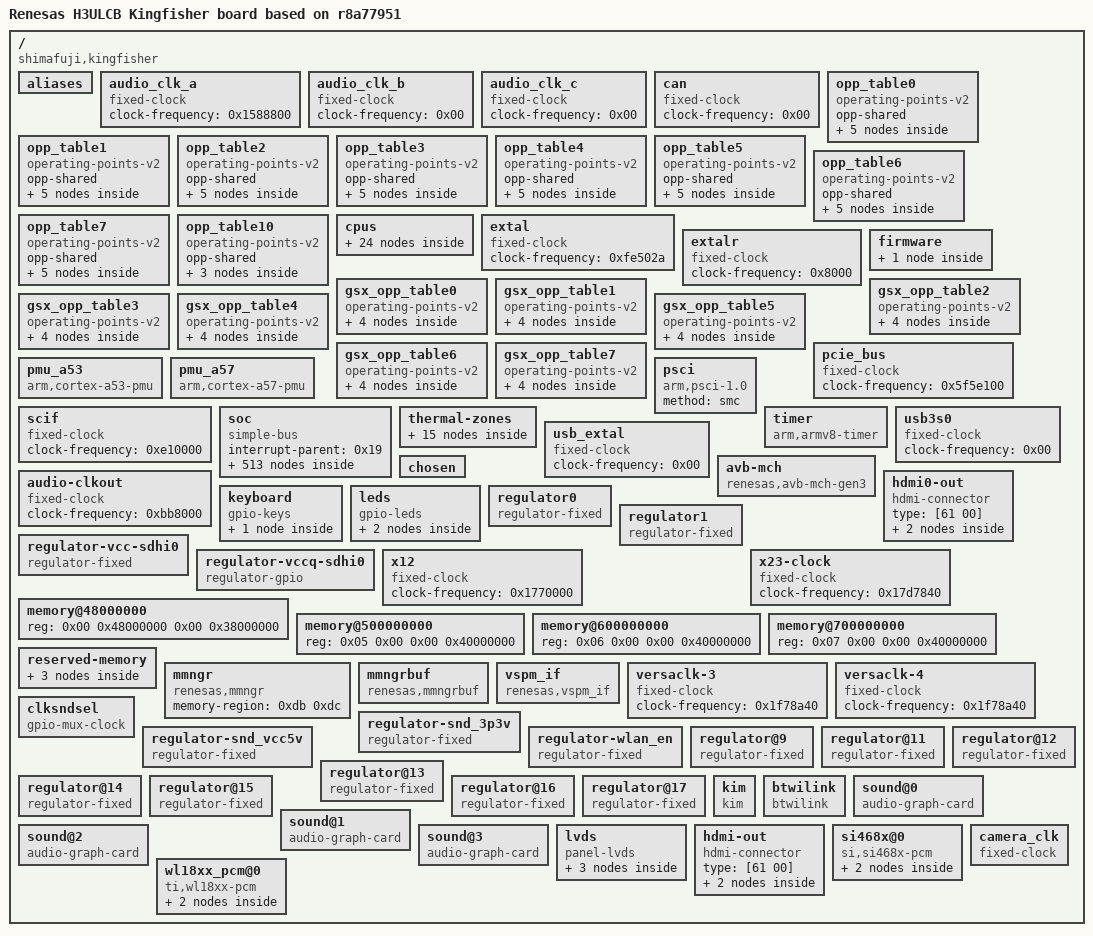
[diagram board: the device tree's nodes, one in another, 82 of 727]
/dts-v1/;

/ {
	compatible = "shimafuji,kingfisher\0renesas,h3ulcb\0renesas,r8a7795";
	#address-cells = <0x02>;
	#size-cells = <0x02>;
	model = "Renesas H3ULCB Kingfisher board based on r8a77951";

	aliases {
		i2c0 = "/soc/i2c@e6500000";
		i2c1 = "/soc/i2c@e6508000";
		i2c2 = "/soc/i2c@e6510000";
		i2c3 = "/soc/i2c@e66d0000";
		i2c4 = "/soc/i2c@e66d8000";
		i2c5 = "/soc/i2c@e66e0000";
		i2c6 = "/soc/i2c@e66e8000";
		i2c7 = "/soc/i2c@e60b0000";
		spi0 = "/soc/spi@e6e90000";
		spi1 = "/soc/spi@e6ea0000";
		spi2 = "/soc/spi@e6c00000";
		spi3 = "/soc/spi@e6c10000";
		serial0 = "/soc/serial@e6e88000";
		ethernet0 = "/soc/ethernet@e6800000";
		mmc0 = "/soc/mmc@ee140000";
		mmc1 = "/soc/mmc@ee100000";
		serial1 = "/soc/serial@e6540000";
		serial2 = "/soc/serial@e6e68000";
		serial3 = "/soc/serial@e6550000";
		mmc2 = "/soc/mmc@ee160000";
	};

	audio_clk_a {
		compatible = "fixed-clock";
		#clock-cells = <0x00>;
		clock-frequency = <0x1588800>;
		phandle = <0x77>;
	};

	audio_clk_b {
		compatible = "fixed-clock";
		#clock-cells = <0x00>;
		clock-frequency = <0x00>;
	};

	audio_clk_c {
		compatible = "fixed-clock";
		#clock-cells = <0x00>;
		clock-frequency = <0x00>;
		phandle = <0x78>;
	};

	can {
		compatible = "fixed-clock";
		#clock-cells = <0x00>;
		clock-frequency = <0x00>;
		phandle = <0x56>;
	};

	opp_table0 {
		compatible = "operating-points-v2";
		opp-shared;
		phandle = <0x0d>;

		opp-500000000 {
			opp-hz = <0x00 0x1dcd6500>;
			opp-microvolt = <0xcaa30>;
			clock-latency-ns = <0x493e0>;
		};

		opp-1000000000 {
			opp-hz = <0x00 0x3b9aca00>;
			opp-microvolt = <0xcaa30>;
			clock-latency-ns = <0x493e0>;
		};

		opp-1500000000 {
			opp-hz = <0x00 0x59682f00>;
			opp-microvolt = <0xcaa30>;
			clock-latency-ns = <0x493e0>;
			opp-suspend;
		};

		opp-1600000000 {
			opp-hz = <0x00 0x5f5e1000>;
			opp-microvolt = <0xdbba0>;
			clock-latency-ns = <0x493e0>;
			turbo-mode;
		};

		opp-1700000000 {
			opp-hz = <0x00 0x6553f100>;
			opp-microvolt = <0xea600>;
			clock-latency-ns = <0x493e0>;
			turbo-mode;
		};
	};

	opp_table1 {
		compatible = "operating-points-v2";
		opp-shared;
		phandle = <0x0e>;

		opp-500000000 {
			opp-hz = <0x00 0x1dcd6500>;
			opp-microvolt = <0xc8320>;
			clock-latency-ns = <0x493e0>;
		};

		opp-1000000000 {
			opp-hz = <0x00 0x3b9aca00>;
			opp-microvolt = <0xc8320>;
			clock-latency-ns = <0x493e0>;
		};

		opp-1500000000 {
			opp-hz = <0x00 0x59682f00>;
			opp-microvolt = <0xc8320>;
			clock-latency-ns = <0x493e0>;
			opp-suspend;
		};

		opp-1600000000 {
			opp-hz = <0x00 0x5f5e1000>;
			opp-microvolt = <0xd9490>;
			clock-latency-ns = <0x493e0>;
			turbo-mode;
		};

		opp-1700000000 {
			opp-hz = <0x00 0x6553f100>;
			opp-microvolt = <0xe7ef0>;
			clock-latency-ns = <0x493e0>;
			turbo-mode;
		};
	};

	opp_table2 {
		compatible = "operating-points-v2";
		opp-shared;
		phandle = <0x0f>;

		opp-500000000 {
			opp-hz = <0x00 0x1dcd6500>;
			opp-microvolt = <0xc5c10>;
			clock-latency-ns = <0x493e0>;
		};

		opp-1000000000 {
			opp-hz = <0x00 0x3b9aca00>;
			opp-microvolt = <0xc5c10>;
			clock-latency-ns = <0x493e0>;
		};

		opp-1500000000 {
			opp-hz = <0x00 0x59682f00>;
			opp-microvolt = <0xc5c10>;
			clock-latency-ns = <0x493e0>;
			opp-suspend;
		};

		opp-1600000000 {
			opp-hz = <0x00 0x5f5e1000>;
			opp-microvolt = <0xd6d80>;
			clock-latency-ns = <0x493e0>;
			turbo-mode;
		};

		opp-1700000000 {
			opp-hz = <0x00 0x6553f100>;
			opp-microvolt = <0xe30d0>;
			clock-latency-ns = <0x493e0>;
			turbo-mode;
		};
	};

	opp_table3 {
		compatible = "operating-points-v2";
		opp-shared;
		phandle = <0x10>;

		opp-500000000 {
			opp-hz = <0x00 0x1dcd6500>;
			opp-microvolt = <0xc3500>;
			clock-latency-ns = <0x493e0>;
		};

		opp-1000000000 {
			opp-hz = <0x00 0x3b9aca00>;
			opp-microvolt = <0xc3500>;
			clock-latency-ns = <0x493e0>;
		};

		opp-1500000000 {
			opp-hz = <0x00 0x59682f00>;
			opp-microvolt = <0xc3500>;
			clock-latency-ns = <0x493e0>;
			opp-suspend;
		};

		opp-1600000000 {
			opp-hz = <0x00 0x5f5e1000>;
			opp-microvolt = <0xd4670>;
			clock-latency-ns = <0x493e0>;
			turbo-mode;
		};

		opp-1700000000 {
			opp-hz = <0x00 0x6553f100>;
			opp-microvolt = <0xde2b0>;
			clock-latency-ns = <0x493e0>;
			turbo-mode;
		};
	};

	opp_table4 {
		compatible = "operating-points-v2";
		opp-shared;
		phandle = <0x11>;

		opp-500000000 {
			opp-hz = <0x00 0x1dcd6500>;
			opp-microvolt = <0xc0df0>;
			clock-latency-ns = <0x493e0>;
		};

		opp-1000000000 {
			opp-hz = <0x00 0x3b9aca00>;
			opp-microvolt = <0xc0df0>;
			clock-latency-ns = <0x493e0>;
		};

		opp-1500000000 {
			opp-hz = <0x00 0x59682f00>;
			opp-microvolt = <0xc0df0>;
			clock-latency-ns = <0x493e0>;
			opp-suspend;
		};

		opp-1600000000 {
			opp-hz = <0x00 0x5f5e1000>;
			opp-microvolt = <0xd1f60>;
			clock-latency-ns = <0x493e0>;
			turbo-mode;
		};

		opp-1700000000 {
			opp-hz = <0x00 0x6553f100>;
			opp-microvolt = <0xd9490>;
			clock-latency-ns = <0x493e0>;
			turbo-mode;
		};
	};

	opp_table5 {
		compatible = "operating-points-v2";
		opp-shared;
		phandle = <0x12>;

		opp-500000000 {
			opp-hz = <0x00 0x1dcd6500>;
			opp-microvolt = <0xbe6e0>;
			clock-latency-ns = <0x493e0>;
		};

		opp-1000000000 {
			opp-hz = <0x00 0x3b9aca00>;
			opp-microvolt = <0xbe6e0>;
			clock-latency-ns = <0x493e0>;
		};

		opp-1500000000 {
			opp-hz = <0x00 0x59682f00>;
			opp-microvolt = <0xbe6e0>;
			clock-latency-ns = <0x493e0>;
			opp-suspend;
		};

		opp-1600000000 {
			opp-hz = <0x00 0x5f5e1000>;
			opp-microvolt = <0xcf850>;
			clock-latency-ns = <0x493e0>;
			turbo-mode;
		};

		opp-1700000000 {
			opp-hz = <0x00 0x6553f100>;
			opp-microvolt = <0xd6d80>;
			clock-latency-ns = <0x493e0>;
			turbo-mode;
		};
	};

	opp_table6 {
		compatible = "operating-points-v2";
		opp-shared;
		phandle = <0x13>;

		opp-500000000 {
			opp-hz = <0x00 0x1dcd6500>;
			opp-microvolt = <0xbbfd0>;
			clock-latency-ns = <0x493e0>;
		};

		opp-1000000000 {
			opp-hz = <0x00 0x3b9aca00>;
			opp-microvolt = <0xbbfd0>;
			clock-latency-ns = <0x493e0>;
		};

		opp-1500000000 {
			opp-hz = <0x00 0x59682f00>;
			opp-microvolt = <0xbbfd0>;
			clock-latency-ns = <0x493e0>;
			opp-suspend;
		};

		opp-1600000000 {
			opp-hz = <0x00 0x5f5e1000>;
			opp-microvolt = <0xcd140>;
			clock-latency-ns = <0x493e0>;
			turbo-mode;
		};

		opp-1700000000 {
			opp-hz = <0x00 0x6553f100>;
			opp-microvolt = <0xd4670>;
			clock-latency-ns = <0x493e0>;
			turbo-mode;
		};
	};

	opp_table7 {
		compatible = "operating-points-v2";
		opp-shared;
		phandle = <0x14>;

		opp-500000000 {
			opp-hz = <0x00 0x1dcd6500>;
			opp-microvolt = <0xb98c0>;
			clock-latency-ns = <0x493e0>;
		};

		opp-1000000000 {
			opp-hz = <0x00 0x3b9aca00>;
			opp-microvolt = <0xb98c0>;
			clock-latency-ns = <0x493e0>;
		};

		opp-1500000000 {
			opp-hz = <0x00 0x59682f00>;
			opp-microvolt = <0xb98c0>;
			clock-latency-ns = <0x493e0>;
			opp-suspend;
		};

		opp-1600000000 {
			opp-hz = <0x00 0x5f5e1000>;
			opp-microvolt = <0xcaa30>;
			clock-latency-ns = <0x493e0>;
			turbo-mode;
		};

		opp-1700000000 {
			opp-hz = <0x00 0x6553f100>;
			opp-microvolt = <0xd1f60>;
			clock-latency-ns = <0x493e0>;
			turbo-mode;
		};
	};

	opp_table10 {
		compatible = "operating-points-v2";
		opp-shared;
		phandle = <0x18>;

		opp-800000000 {
			opp-hz = <0x00 0x2faf0800>;
			opp-microvolt = <0xc8320>;
			clock-latency-ns = <0x493e0>;
		};

		opp-1000000000 {
			opp-hz = <0x00 0x3b9aca00>;
			opp-microvolt = <0xc8320>;
			clock-latency-ns = <0x493e0>;
		};

		opp-1200000000 {
			opp-hz = <0x00 0x47868c00>;
			opp-microvolt = <0xc8320>;
			clock-latency-ns = <0x493e0>;
			opp-suspend;
		};
	};

	cpus {
		#address-cells = <0x01>;
		#size-cells = <0x00>;

		cpu-map {

			cluster0 {

				core0 {
					cpu = <0x01>;
				};

				core1 {
					cpu = <0x02>;
				};

				core2 {
					cpu = <0x03>;
				};

				core3 {
					cpu = <0x04>;
				};
			};

			cluster1 {

				core0 {
					cpu = <0x05>;
				};

				core1 {
					cpu = <0x06>;
				};

				core2 {
					cpu = <0x07>;
				};

				core3 {
					cpu = <0x08>;
				};
			};
		};

		cpu@0 {
			compatible = "arm,cortex-a57";
			reg = <0x00>;
			device_type = "cpu";
			power-domains = <0x09 0x00>;
			next-level-cache = <0x0a>;
			enable-method = "psci";
			cpu-idle-states = <0x0b>;
			dynamic-power-coefficient = <0x356>;
			cooling-min-level = <0x00>;
			cooling-max-level = <0x02>;
			clocks = <0x0c 0x00 0x00>;
			operating-points-v2 = <0x0d 0x0e 0x0f 0x10 0x11 0x12 0x13 0x14>;
			capacity-dmips-mhz = <0x400>;
			#cooling-cells = <0x02>;
			cpu-supply = <0x15>;
			phandle = <0x01>;
		};

		cpu@1 {
			compatible = "arm,cortex-a57";
			reg = <0x01>;
			device_type = "cpu";
			power-domains = <0x09 0x01>;
			next-level-cache = <0x0a>;
			enable-method = "psci";
			cpu-idle-states = <0x0b>;
			clocks = <0x0c 0x00 0x00>;
			operating-points-v2 = <0x0d 0x0e 0x0f 0x10 0x11 0x12 0x13 0x14>;
			capacity-dmips-mhz = <0x400>;
			#cooling-cells = <0x02>;
			phandle = <0x02>;
		};

		cpu@2 {
			compatible = "arm,cortex-a57";
			reg = <0x02>;
			device_type = "cpu";
			power-domains = <0x09 0x02>;
			next-level-cache = <0x0a>;
			enable-method = "psci";
			cpu-idle-states = <0x0b>;
			clocks = <0x0c 0x00 0x00>;
			operating-points-v2 = <0x0d 0x0e 0x0f 0x10 0x11 0x12 0x13 0x14>;
			capacity-dmips-mhz = <0x400>;
			#cooling-cells = <0x02>;
			phandle = <0x03>;
		};

		cpu@3 {
			compatible = "arm,cortex-a57";
			reg = <0x03>;
			device_type = "cpu";
			power-domains = <0x09 0x03>;
			next-level-cache = <0x0a>;
			enable-method = "psci";
			cpu-idle-states = <0x0b>;
			clocks = <0x0c 0x00 0x00>;
			operating-points-v2 = <0x0d 0x0e 0x0f 0x10 0x11 0x12 0x13 0x14>;
			capacity-dmips-mhz = <0x400>;
			#cooling-cells = <0x02>;
			phandle = <0x04>;
		};

		cpu@100 {
			compatible = "arm,cortex-a53";
			reg = <0x100>;
			device_type = "cpu";
			power-domains = <0x09 0x05>;
			next-level-cache = <0x16>;
			enable-method = "psci";
			cpu-idle-states = <0x17>;
			#cooling-cells = <0x02>;
			dynamic-power-coefficient = <0x115>;
			cooling-min-level = <0x00>;
			cooling-max-level = <0x02>;
			clocks = <0x0c 0x00 0x01>;
			operating-points-v2 = <0x18>;
			capacity-dmips-mhz = <0x21c>;
			phandle = <0x05>;
		};

		cpu@101 {
			compatible = "arm,cortex-a53";
			reg = <0x101>;
			device_type = "cpu";
			power-domains = <0x09 0x06>;
			next-level-cache = <0x16>;
			enable-method = "psci";
			cpu-idle-states = <0x17>;
			clocks = <0x0c 0x00 0x01>;
			operating-points-v2 = <0x18>;
			capacity-dmips-mhz = <0x21c>;
			phandle = <0x06>;
		};

		cpu@102 {
			compatible = "arm,cortex-a53";
			reg = <0x102>;
			device_type = "cpu";
			power-domains = <0x09 0x07>;
			next-level-cache = <0x16>;
			enable-method = "psci";
			cpu-idle-states = <0x17>;
			clocks = <0x0c 0x00 0x01>;
			operating-points-v2 = <0x18>;
			capacity-dmips-mhz = <0x21c>;
			phandle = <0x07>;
		};

		cpu@103 {
			compatible = "arm,cortex-a53";
			reg = <0x103>;
			device_type = "cpu";
			power-domains = <0x09 0x08>;
			next-level-cache = <0x16>;
			enable-method = "psci";
			cpu-idle-states = <0x17>;
			clocks = <0x0c 0x00 0x01>;
			operating-points-v2 = <0x18>;
			capacity-dmips-mhz = <0x21c>;
			phandle = <0x08>;
		};

		cache-controller-0 {
			compatible = "cache";
			power-domains = <0x09 0x0c>;
			cache-unified;
			cache-level = <0x02>;
			phandle = <0x0a>;
		};

		cache-controller-1 {
			compatible = "cache";
			power-domains = <0x09 0x15>;
			cache-unified;
			cache-level = <0x02>;
			phandle = <0x16>;
		};

		idle-states {
			entry-method = "psci";

			cpu-sleep-0 {
				compatible = "arm,idle-state";
				arm,psci-suspend-param = <0x10000>;
				local-timer-stop;
				entry-latency-us = <0x190>;
				exit-latency-us = <0x1f4>;
				min-residency-us = <0xfa0>;
				phandle = <0x0b>;
			};

			cpu-sleep-1 {
				compatible = "arm,idle-state";
				arm,psci-suspend-param = <0x10000>;
				local-timer-stop;
				entry-latency-us = <0x2bc>;
				exit-latency-us = <0x2bc>;
				min-residency-us = <0x1388>;
				phandle = <0x17>;
			};
		};
	};

	extal {
		compatible = "fixed-clock";
		#clock-cells = <0x00>;
		clock-frequency = <0xfe502a>;
		phandle = <0x1d>;
	};

	extalr {
		compatible = "fixed-clock";
		#clock-cells = <0x00>;
		clock-frequency = <0x8000>;
		phandle = <0x1e>;
	};

	firmware {

		optee {
			compatible = "linaro,optee-tz";
			method = "smc";
		};
	};

	gsx_opp_table0 {
		compatible = "operating-points-v2";
		phandle = <0xa3>;

		opp-200000000 {
			opp-hz = <0x00 0xbebc200>;
			opp-microvolt = <0xcaa30>;
		};

		opp-300000000 {
			opp-hz = <0x00 0x11e1a300>;
			opp-microvolt = <0xcaa30>;
		};

		opp-400000000 {
			opp-hz = <0x00 0x17d78400>;
			opp-microvolt = <0xcaa30>;
		};

		opp-600000000 {
			opp-hz = <0x00 0x23c34600>;
			opp-microvolt = <0xcaa30>;
		};
	};

	gsx_opp_table1 {
		compatible = "operating-points-v2";
		phandle = <0xa4>;

		opp-200000000 {
			opp-hz = <0x00 0xbebc200>;
			opp-microvolt = <0xc8320>;
		};

		opp-300000000 {
			opp-hz = <0x00 0x11e1a300>;
			opp-microvolt = <0xc8320>;
		};

		opp-400000000 {
			opp-hz = <0x00 0x17d78400>;
			opp-microvolt = <0xc8320>;
		};

		opp-600000000 {
			opp-hz = <0x00 0x23c34600>;
			opp-microvolt = <0xc8320>;
		};
	};

	gsx_opp_table2 {
		compatible = "operating-points-v2";
		phandle = <0xa5>;

		opp-200000000 {
			opp-hz = <0x00 0xbebc200>;
			opp-microvolt = <0xc5c10>;
		};

		opp-300000000 {
			opp-hz = <0x00 0x11e1a300>;
			opp-microvolt = <0xc5c10>;
		};

		opp-400000000 {
			opp-hz = <0x00 0x17d78400>;
			opp-microvolt = <0xc5c10>;
		};

		opp-600000000 {
			opp-hz = <0x00 0x23c34600>;
			opp-microvolt = <0xc5c10>;
		};
	};

	gsx_opp_table3 {
		compatible = "operating-points-v2";
		phandle = <0xa6>;

		opp-200000000 {
			opp-hz = <0x00 0xbebc200>;
			opp-microvolt = <0xc3500>;
		};

		opp-300000000 {
			opp-hz = <0x00 0x11e1a300>;
			opp-microvolt = <0xc3500>;
		};

		opp-400000000 {
			opp-hz = <0x00 0x17d78400>;
			opp-microvolt = <0xc3500>;
		};

		opp-600000000 {
			opp-hz = <0x00 0x23c34600>;
			opp-microvolt = <0xc3500>;
		};
	};

	gsx_opp_table4 {
		compatible = "operating-points-v2";
		phandle = <0xa7>;

		opp-200000000 {
			opp-hz = <0x00 0xbebc200>;
			opp-microvolt = <0xc0df0>;
		};

		opp-300000000 {
			opp-hz = <0x00 0x11e1a300>;
			opp-microvolt = <0xc0df0>;
		};

		opp-400000000 {
			opp-hz = <0x00 0x17d78400>;
			opp-microvolt = <0xc0df0>;
		};

		opp-600000000 {
			opp-hz = <0x00 0x23c34600>;
			opp-microvolt = <0xc0df0>;
		};
	};

	gsx_opp_table5 {
		compatible = "operating-points-v2";
		phandle = <0xa8>;

		opp-200000000 {
			opp-hz = <0x00 0xbebc200>;
			opp-microvolt = <0xbe6e0>;
		};

		opp-300000000 {
			opp-hz = <0x00 0x11e1a300>;
			opp-microvolt = <0xbe6e0>;
		};

		opp-400000000 {
			opp-hz = <0x00 0x17d78400>;
			opp-microvolt = <0xbe6e0>;
		};

		opp-600000000 {
			opp-hz = <0x00 0x23c34600>;
			opp-microvolt = <0xbe6e0>;
		};
	};

	gsx_opp_table6 {
		compatible = "operating-points-v2";
		phandle = <0xa9>;

		opp-200000000 {
			opp-hz = <0x00 0xbebc200>;
			opp-microvolt = <0xbbfd0>;
		};

		opp-300000000 {
			opp-hz = <0x00 0x11e1a300>;
			opp-microvolt = <0xbbfd0>;
		};

		opp-400000000 {
			opp-hz = <0x00 0x17d78400>;
			opp-microvolt = <0xbbfd0>;
		};

		opp-600000000 {
			opp-hz = <0x00 0x23c34600>;
			opp-microvolt = <0xbbfd0>;
		};
	};

	gsx_opp_table7 {
		compatible = "operating-points-v2";
		phandle = <0xaa>;

		opp-200000000 {
			opp-hz = <0x00 0xbebc200>;
			opp-microvolt = <0xb98c0>;
		};

		opp-300000000 {
			opp-hz = <0x00 0x11e1a300>;
			opp-microvolt = <0xb98c0>;
		};

		opp-400000000 {
			opp-hz = <0x00 0x17d78400>;
			opp-microvolt = <0xb98c0>;
		};

		opp-600000000 {
			opp-hz = <0x00 0x23c34600>;
			opp-microvolt = <0xb98c0>;
		};
	};

	pcie_bus {
		compatible = "fixed-clock";
		#clock-cells = <0x00>;
		clock-frequency = <0x5f5e100>;
		status = "okay";
		phandle = <0xab>;
	};

	pmu_a53 {
		compatible = "arm,cortex-a53-pmu";
		interrupts-extended = <0x19 0x00 0x54 0x04 0x19 0x00 0x55 0x04 0x19 0x00 0x56 0x04 0x19 0x00 0x57 0x04>;
		interrupt-affinity = <0x05 0x06 0x07 0x08>;
	};

	pmu_a57 {
		compatible = "arm,cortex-a57-pmu";
		interrupts-extended = <0x19 0x00 0x48 0x04 0x19 0x00 0x49 0x04 0x19 0x00 0x4a 0x04 0x19 0x00 0x4b 0x04>;
		interrupt-affinity = <0x01 0x02 0x03 0x04>;
	};

	psci {
		compatible = "arm,psci-1.0\0arm,psci-0.2";
		method = "smc";
	};

	scif {
		compatible = "fixed-clock";
		#clock-cells = <0x00>;
		clock-frequency = <0xe10000>;
		phandle = <0x47>;
	};

	soc {
		compatible = "simple-bus";
		interrupt-parent = <0x19>;
		#address-cells = <0x02>;
		#size-cells = <0x02>;
		ranges;

		mfis@e6260000 {
			compatible = "renesas,mfis-lock-r8a7795\0renesas,mfis-lock";
			reg = <0x00 0xe6260000 0x00 0x1000>;
			#hwlock-cells = <0x01>;
		};

		watchdog@e6020000 {
			compatible = "renesas,r8a7795-wdt\0renesas,rcar-gen3-wdt";
			reg = <0x00 0xe6020000 0x00 0x0c>;
			clocks = <0x0c 0x01 0x192>;
			power-domains = <0x09 0x20>;
			resets = <0x0c 0x192>;
			status = "okay";
			timeout-sec = <0x3c>;
		};

		gpio@e6050000 {
			compatible = "renesas,gpio-r8a7795\0renesas,rcar-gen3-gpio";
			reg = <0x00 0xe6050000 0x00 0x50>;
			interrupts = <0x00 0x04 0x04>;
			#gpio-cells = <0x02>;
			gpio-controller;
			gpio-ranges = <0x1a 0x00 0x00 0x10>;
			#interrupt-cells = <0x02>;
			interrupt-controller;
			clocks = <0x0c 0x01 0x390>;
			power-domains = <0x09 0x20>;
			resets = <0x0c 0x390>;
		};

		gpio@e6051000 {
			compatible = "renesas,gpio-r8a7795\0renesas,rcar-gen3-gpio";
			reg = <0x00 0xe6051000 0x00 0x50>;
			interrupts = <0x00 0x05 0x04>;
			#gpio-cells = <0x02>;
			gpio-controller;
			gpio-ranges = <0x1a 0x00 0x20 0x1d>;
			#interrupt-cells = <0x02>;
			interrupt-controller;
			clocks = <0x0c 0x01 0x38f>;
			power-domains = <0x09 0x20>;
			resets = <0x0c 0x38f>;
			phandle = <0xa2>;
		};

		gpio@e6052000 {
			compatible = "renesas,gpio-r8a7795\0renesas,rcar-gen3-gpio";
			reg = <0x00 0xe6052000 0x00 0x50>;
			interrupts = <0x00 0x06 0x04>;
			#gpio-cells = <0x02>;
			gpio-controller;
			gpio-ranges = <0x1a 0x00 0x40 0x0f>;
			#interrupt-cells = <0x02>;
			interrupt-controller;
			clocks = <0x0c 0x01 0x38e>;
			power-domains = <0x09 0x20>;
			resets = <0x0c 0x38e>;
			phandle = <0x55>;

			gpio@3 {
				gpio-hog;
				gpios = <0x03 0x00>;
				output-high;
				line-name = "BL PWM 100%";
			};
		};

		gpio@e6053000 {
			compatible = "renesas,gpio-r8a7795\0renesas,rcar-gen3-gpio";
			reg = <0x00 0xe6053000 0x00 0x50>;
			interrupts = <0x00 0x07 0x04>;
			#gpio-cells = <0x02>;
			gpio-controller;
			gpio-ranges = <0x1a 0x00 0x60 0x10>;
			#interrupt-cells = <0x02>;
			interrupt-controller;
			clocks = <0x0c 0x01 0x38d>;
			power-domains = <0x09 0x20>;
			resets = <0x0c 0x38d>;
			phandle = <0x32>;
		};

		gpio@e6054000 {
			compatible = "renesas,gpio-r8a7795\0renesas,rcar-gen3-gpio";
			reg = <0x00 0xe6054000 0x00 0x50>;
			interrupts = <0x00 0x08 0x04>;
			#gpio-cells = <0x02>;
			gpio-controller;
			gpio-ranges = <0x1a 0x00 0x80 0x12>;
			#interrupt-cells = <0x02>;
			interrupt-controller;
			clocks = <0x0c 0x01 0x38c>;
			power-domains = <0x09 0x20>;
			resets = <0x0c 0x38c>;

			most_rst {
				gpio-hog;
				gpios = <0x0e 0x00>;
				output-high;
				line-name = "MOST RST";
			};
		};

		gpio@e6055000 {
			compatible = "renesas,gpio-r8a7795\0renesas,rcar-gen3-gpio";
			reg = <0x00 0xe6055000 0x00 0x50>;
			interrupts = <0x00 0x09 0x04>;
			#gpio-cells = <0x02>;
			gpio-controller;
			gpio-ranges = <0x1a 0x00 0xa0 0x1a>;
			#interrupt-cells = <0x02>;
			interrupt-controller;
			clocks = <0x0c 0x01 0x38b>;
			power-domains = <0x09 0x20>;
			resets = <0x0c 0x38b>;
			phandle = <0x27>;
		};

		gpio@e6055400 {
			compatible = "renesas,gpio-r8a7795\0renesas,rcar-gen3-gpio";
			reg = <0x00 0xe6055400 0x00 0x50>;
			interrupts = <0x00 0x0a 0x04>;
			#gpio-cells = <0x02>;
			gpio-controller;
			gpio-ranges = <0x1a 0x00 0xc0 0x20>;
			#interrupt-cells = <0x02>;
			interrupt-controller;
			clocks = <0x0c 0x01 0x38a>;
			power-domains = <0x09 0x20>;
			resets = <0x0c 0x38a>;
			phandle = <0x2f>;

			audio_sw {
				gpio-hog;
				gpios = <0x15 0x00>;
				output-high;
				line-name = "Onboard MCh Audio";
			};
		};

		gpio@e6055800 {
			compatible = "renesas,gpio-r8a7795\0renesas,rcar-gen3-gpio";
			reg = <0x00 0xe6055800 0x00 0x50>;
			interrupts = <0x00 0x0b 0x04>;
			#gpio-cells = <0x02>;
			gpio-controller;
			gpio-ranges = <0x1a 0x00 0xe0 0x04>;
			#interrupt-cells = <0x02>;
			interrupt-controller;
			clocks = <0x0c 0x01 0x389>;
			power-domains = <0x09 0x20>;
			resets = <0x0c 0x389>;
			phandle = <0x44>;
		};

		pinctrl@e6060000 {
			compatible = "renesas,pfc-r8a7795";
			reg = <0x00 0xe6060000 0x00 0x50c>;
			pinctrl-0 = <0x1b>;
			pinctrl-names = "default";
			phandle = <0x1a>;

			avb {
				phandle = <0x53>;

				mux {
					groups = "avb_link\0avb_mdio\0avb_mii";
					function = "avb";
				};

				pins_mdio {
					groups = "avb_mdio";
					drive-strength = <0x18>;
				};

				pins_mii_tx {
					pins = "PIN_AVB_TX_CTL\0PIN_AVB_TXC\0PIN_AVB_TD0\0PIN_AVB_TD1\0PIN_AVB_TD2\0PIN_AVB_TD3";
					drive-strength = <0x0c>;
				};
			};

			i2c2 {
				groups = "i2c2_a";
				function = "i2c2";
				phandle = <0x21>;
			};

			irq0 {
				groups = "intc_ex_irq0";
				function = "intc_ex";
				phandle = <0x45>;
			};

			scif2 {
				groups = "scif2_data_a";
				function = "scif2";
				phandle = <0x5c>;
			};

			scif_clk {
				groups = "scif_clk_a";
				function = "scif_clk";
				phandle = <0x1b>;
			};

			sd0 {
				groups = "sdhi0_data4\0sdhi0_ctrl";
				function = "sdhi0";
				power-source = <0xce4>;
				phandle = <0x98>;
			};

			sd0_uhs {
				groups = "sdhi0_data4\0sdhi0_ctrl";
				function = "sdhi0";
				power-source = <0x708>;
				phandle = <0x99>;
			};

			sd2 {
				groups = "sdhi2_data8\0sdhi2_ctrl\0sdhi2_ds";
				function = "sdhi2";
				power-source = <0x708>;
				phandle = <0x9c>;
			};

			sound {
				groups = "ssi01239_ctrl\0ssi0_data\0ssi1_data_a";
				function = "ssi";
				phandle = <0x79>;
			};

			sound-clk {
				groups = "audio_clk_a_a\0audio_clk_b_a\0audio_clk_c_a\0audio_clkout_a\0audio_clkout3_a";
				function = "audio_clk";
				phandle = <0x7a>;
			};

			usb1 {
				groups = "usb1";
				function = "usb1";
				phandle = <0x97>;
			};

			can0 {
				groups = "can0_data_a";
				function = "can0";
				phandle = <0x57>;
			};

			can1 {
				groups = "can1_data";
				function = "can1";
				phandle = <0x58>;
			};

			canfd0 {
				groups = "canfd0_data_a";
				function = "canfd0";
				phandle = <0x59>;
			};

			canfd1 {
				groups = "canfd1_data";
				function = "canfd1";
				phandle = <0x5a>;
			};

			du {
				groups = "du_rgb888\0du_sync\0du_clk_out_0\0du_disp";
				function = "du";
				phandle = <0xd0>;
			};

			hscif0 {
				groups = "hscif0_data\0hscif0_ctrl";
				function = "hscif0";
				phandle = <0x48>;
			};

			hscif1 {
				groups = "hscif1_data_a\0hscif1_ctrl_a";
				function = "hscif1";
				phandle = <0x49>;
			};

			scif1 {
				groups = "scif1_data_b";
				function = "scif1";
				phandle = <0x5b>;
			};

			sdhi3 {
				groups = "sdhi3_data4\0sdhi3_ctrl";
				function = "sdhi3";
				power-source = <0xce4>;
				phandle = <0xa0>;
			};

			sound-pcm {
				groups = "ssi349_ctrl\0ssi3_data\0ssi4_data\0ssi6_ctrl\0ssi6_data\0ssi78_ctrl\0ssi7_data\0ssi8_data";
				function = "ssi";
				phandle = <0x7b>;
			};

			usb0 {
				groups = "usb0";
				function = "usb0";
				phandle = <0x96>;
			};

			vin5 {
				groups = "vin5_data8\0vin5_sync\0vin5_clk";
				function = "vin5";
				phandle = <0x67>;
			};
		};

		timer@e60f0000 {
			compatible = "renesas,r8a7795-cmt0\0renesas,rcar-gen3-cmt0";
			reg = <0x00 0xe60f0000 0x00 0x1004>;
			interrupts = <0x00 0x8e 0x04 0x00 0x8f 0x04>;
			clocks = <0x0c 0x01 0x12f>;
			clock-names = "fck";
			power-domains = <0x09 0x20>;
			resets = <0x0c 0x12f>;
			status = "disabled";
		};

		timer@e6130000 {
			compatible = "renesas,r8a7795-cmt1\0renesas,rcar-gen3-cmt1";
			reg = <0x00 0xe6130000 0x00 0x1004>;
			interrupts = <0x00 0x78 0x04 0x00 0x79 0x04 0x00 0x7a 0x04 0x00 0x7b 0x04 0x00 0x7c 0x04 0x00 0x7d 0x04 0x00 0x7e 0x04 0x00 0x7f 0x04>;
			clocks = <0x0c 0x01 0x12e>;
			clock-names = "fck";
			power-domains = <0x09 0x20>;
			resets = <0x0c 0x12e>;
			status = "disabled";
		};

		timer@e6140000 {
			compatible = "renesas,r8a7795-cmt1\0renesas,rcar-gen3-cmt1";
			reg = <0x00 0xe6140000 0x00 0x1004>;
			interrupts = <0x00 0x18e 0x04 0x00 0x18f 0x04 0x00 0x190 0x04 0x00 0x191 0x04 0x00 0x192 0x04 0x00 0x193 0x04 0x00 0x194 0x04 0x00 0x195 0x04>;
			clocks = <0x0c 0x01 0x12d>;
			clock-names = "fck";
			power-domains = <0x09 0x20>;
			resets = <0x0c 0x12d>;
			status = "disabled";
		};

		timer@e6148000 {
			compatible = "renesas,r8a7795-cmt1\0renesas,rcar-gen3-cmt1";
			reg = <0x00 0xe6148000 0x00 0x1004>;
			interrupts = <0x00 0x1d6 0x04 0x00 0x1d7 0x04 0x00 0x1d8 0x04 0x00 0x1d9 0x04 0x00 0x1da 0x04 0x00 0x1db 0x04 0x00 0x1dc 0x04 0x00 0x1dd 0x04>;
			clocks = <0x0c 0x01 0x12c>;
			clock-names = "fck";
			power-domains = <0x09 0x20>;
			resets = <0x0c 0x12c>;
			status = "disabled";
		};

		avs@e60a013c {
			compatible = "renesas,r8a77951-avs\0renesas,rcar-gen3-avs";
			reg = <0x00 0xe60a013c 0x00 0x04>;
			clocks = <0x0c 0x01 0x39d>;
			resets = <0x0c 0x39d>;
			target_devices = <0x01 0x02 0x03 0x04 0x1c>;
		};

		clock-controller@e6150000 {
			compatible = "renesas,r8a7795-cpg-mssr";
			reg = <0x00 0xe6150000 0x00 0x1000>;
			clocks = <0x1d 0x1e>;
			clock-names = "extal\0extalr";
			#clock-cells = <0x02>;
			#power-domain-cells = <0x00>;
			#reset-cells = <0x01>;
			phandle = <0x0c>;
		};

		reset-controller@e6160000 {
			compatible = "renesas,r8a7795-rst";
			reg = <0x00 0xe6160000 0x00 0x200>;
		};

		system-controller@e6180000 {
			compatible = "renesas,r8a7795-sysc";
			reg = <0x00 0xe6180000 0x00 0x400>;
			#power-domain-cells = <0x01>;
			phandle = <0x09>;
		};

		thermal@e6198000 {
			compatible = "renesas,r8a7795-thermal";
			reg = <0x00 0xe6198000 0x00 0x100 0x00 0xe61a0000 0x00 0x100 0x00 0xe61a8000 0x00 0x100>;
			interrupts = <0x00 0x43 0x04 0x00 0x44 0x04 0x00 0x45 0x04>;
			clocks = <0x0c 0x01 0x20a>;
			power-domains = <0x09 0x20>;
			resets = <0x0c 0x20a>;
			#thermal-sensor-cells = <0x01>;
			phandle = <0xd8>;
		};

		interrupt-controller@e61c0000 {
			compatible = "renesas,intc-ex-r8a7795\0renesas,irqc";
			#interrupt-cells = <0x02>;
			interrupt-controller;
			reg = <0x00 0xe61c0000 0x00 0x200>;
			interrupts = <0x00 0x00 0x04 0x00 0x01 0x04 0x00 0x02 0x04 0x00 0x03 0x04 0x00 0x12 0x04 0x00 0xa1 0x04>;
			power-domains = <0x09 0x20>;
			phandle = <0x46>;
		};

		timer@e61e0000 {
			compatible = "renesas,tmu-r8a7795\0renesas,tmu";
			reg = <0x00 0xe61e0000 0x00 0x30>;
			interrupts = <0x00 0x88 0x04 0x00 0x89 0x04 0x00 0x8a 0x04>;
			clocks = <0x0c 0x01 0x7d>;
			clock-names = "fck";
			power-domains = <0x09 0x20>;
			resets = <0x0c 0x7d>;
			status = "disabled";
		};

		timer@e6fc0000 {
			compatible = "renesas,tmu-r8a7795\0renesas,tmu";
			reg = <0x00 0xe6fc0000 0x00 0x30>;
			interrupts = <0x00 0x80 0x04 0x00 0x81 0x04 0x00 0x82 0x04>;
			clocks = <0x0c 0x01 0x7c>;
			clock-names = "fck";
			power-domains = <0x09 0x20>;
			resets = <0x0c 0x7c>;
			status = "disabled";
		};

		timer@e6fd0000 {
			compatible = "renesas,tmu-r8a7795\0renesas,tmu";
			reg = <0x00 0xe6fd0000 0x00 0x30>;
			interrupts = <0x00 0x12f 0x04 0x00 0x130 0x04 0x00 0x131 0x04>;
			clocks = <0x0c 0x01 0x7b>;
			clock-names = "fck";
			power-domains = <0x09 0x20>;
			resets = <0x0c 0x7b>;
			status = "disabled";
		};

		timer@e6fe0000 {
			compatible = "renesas,tmu-r8a7795\0renesas,tmu";
			reg = <0x00 0xe6fe0000 0x00 0x30>;
			interrupts = <0x00 0x83 0x04 0x00 0x84 0x04 0x00 0x85 0x04>;
			clocks = <0x0c 0x01 0x7a>;
			clock-names = "fck";
			power-domains = <0x09 0x20>;
			resets = <0x0c 0x7a>;
			status = "disabled";
		};

		timer@ffc00000 {
			compatible = "renesas,tmu-r8a7795\0renesas,tmu";
			reg = <0x00 0xffc00000 0x00 0x30>;
			interrupts = <0x00 0x196 0x04 0x00 0x197 0x04 0x00 0x198 0x04>;
			clocks = <0x0c 0x01 0x79>;
			clock-names = "fck";
			power-domains = <0x09 0x20>;
			resets = <0x0c 0x79>;
			status = "disabled";
		};

		i2c@e6500000 {
			#address-cells = <0x01>;
			#size-cells = <0x00>;
			compatible = "renesas,i2c-r8a7795\0renesas,rcar-gen3-i2c";
			reg = <0x00 0xe6500000 0x00 0x40>;
			interrupts = <0x00 0x11f 0x04>;
			clocks = <0x0c 0x01 0x3a3>;
			power-domains = <0x09 0x20>;
			resets = <0x0c 0x3a3>;
			dmas = <0x1f 0x91 0x1f 0x90 0x20 0x91 0x20 0x90>;
			dma-names = "tx\0rx\0tx\0rx";
			i2c-scl-internal-delay-ns = <0x6e>;
			status = "disabled";
		};

		i2c@e6508000 {
			#address-cells = <0x01>;
			#size-cells = <0x00>;
			compatible = "renesas,i2c-r8a7795\0renesas,rcar-gen3-i2c";
			reg = <0x00 0xe6508000 0x00 0x40>;
			interrupts = <0x00 0x120 0x04>;
			clocks = <0x0c 0x01 0x3a2>;
			power-domains = <0x09 0x20>;
			resets = <0x0c 0x3a2>;
			dmas = <0x1f 0x93 0x1f 0x92 0x20 0x93 0x20 0x92>;
			dma-names = "tx\0rx\0tx\0rx";
			i2c-scl-internal-delay-ns = <0x06>;
			status = "disabled";
		};

		i2c@e6510000 {
			#address-cells = <0x01>;
			#size-cells = <0x00>;
			compatible = "renesas,i2c-r8a7795\0renesas,rcar-gen3-i2c";
			reg = <0x00 0xe6510000 0x00 0x40>;
			interrupts = <0x00 0x11e 0x04>;
			clocks = <0x0c 0x01 0x3a1>;
			power-domains = <0x09 0x20>;
			resets = <0x0c 0x3a1>;
			dmas = <0x1f 0x95 0x1f 0x94 0x20 0x95 0x20 0x94>;
			dma-names = "tx\0rx\0tx\0rx";
			i2c-scl-internal-delay-ns = <0x06>;
			status = "okay";
			pinctrl-0 = <0x21>;
			pinctrl-names = "default";
			clock-frequency = <0x186a0>;

			codec@10 {
				compatible = "asahi-kasei,ak4613";
				#sound-dai-cells = <0x00>;
				reg = <0x10>;
				clocks = <0x22 0x03>;
				asahi-kasei,in1-single-end;
				asahi-kasei,in2-single-end;
				asahi-kasei,out1-single-end;
				asahi-kasei,out2-single-end;
				asahi-kasei,out3-single-end;
				asahi-kasei,out4-single-end;
				asahi-kasei,out5-single-end;
				asahi-kasei,out6-single-end;

				port {

					endpoint {
						remote-endpoint = <0x23>;
						phandle = <0x7e>;
					};
				};
			};

			clk-multiplier@4f {
				#clock-cells = <0x00>;
				compatible = "cirrus,cs2000-cp";
				reg = <0x4f>;
				clocks = <0x24 0x25>;
				clock-names = "clk_in\0ref_clk";
				assigned-clocks = <0x26>;
				assigned-clock-rates = <0x1770000>;
				phandle = <0x26>;
			};

			i2c-switch@71 {
				compatible = "nxp,pca9548";
				#address-cells = <0x01>;
				#size-cells = <0x00>;
				reg = <0x71>;
				reset-gpios = <0x27 0x03 0x01>;
				i2c-mux-idle-disconnect;

				i2c@0 {
					#address-cells = <0x01>;
					#size-cells = <0x00>;
					reg = <0x00>;
				};

				i2c@1 {
					#address-cells = <0x01>;
					#size-cells = <0x00>;
					reg = <0x01>;
				};

				i2c@2 {
					#address-cells = <0x01>;
					#size-cells = <0x00>;
					reg = <0x02>;
				};

				i2c@3 {
					#address-cells = <0x01>;
					#size-cells = <0x00>;
					reg = <0x03>;
				};

				i2c@4 {
					#address-cells = <0x01>;
					#size-cells = <0x00>;
					reg = <0x04>;

					hdmi@3d {
						compatible = "adi,adv7513";
						reg = <0x3d>;
						pd-gpios = <0x28 0x05 0x01>;
						interlace-allowed;
						adi,input-depth = <0x08>;
						adi,input-colorspace = "rgb";
						adi,input-clock = "1x";
						adi,input-style = <0x01>;
						adi,input-justification = "evenly";
						adi,clock-delay = <0x4b0>;
						limit-frequency = <0x5f5e100>;

						ports {
							#address-cells = <0x01>;
							#size-cells = <0x00>;

							port@0 {
								reg = <0x00>;

								endpoint {
									remote-endpoint = <0x29>;
									phandle = <0xd1>;
								};
							};

							port@1 {
								reg = <0x01>;

								endpoint {
									remote-endpoint = <0x2a>;
									phandle = <0xe5>;
								};
							};
						};
					};
				};

				i2c@5 {
					#address-cells = <0x01>;
					#size-cells = <0x00>;
					reg = <0x05>;
				};

				i2c@6 {
					#address-cells = <0x01>;
					#size-cells = <0x00>;
					reg = <0x06>;

					edt-ft5x06@38 {
						compatible = "edt,edt-ft5x06";
						reg = <0x38>;
						interrupt-parent = <0x27>;
						interrupts = <0x06 0x02>;
					};
				};

				i2c@7 {
					#address-cells = <0x01>;
					#size-cells = <0x00>;
					reg = <0x07>;

					audio-codec@44 {
						#sound-dai-cells = <0x00>;
						compatible = "ti,pcm3168a";
						reg = <0x44>;
						clocks = <0x2b>;
						clock-names = "scki";
						tdm;
						VDD1-supply = <0x2c>;
						VDD2-supply = <0x2c>;
						VCCAD1-supply = <0x2d>;
						VCCAD2-supply = <0x2d>;
						VCCDA1-supply = <0x2d>;
						VCCDA2-supply = <0x2d>;

						port {

							endpoint {
								remote-endpoint = <0x2e>;
								clocks = <0x2b>;
								phandle = <0x88>;
							};
						};
					};

					lsm9ds0_acc_mag@1d {
						compatible = "st,lsm9ds0";
						reg = <0x1d>;
					};

					lsm9ds0_gyr@6b {
						compatible = "st,lsm9ds0";
						reg = <0x6b>;
					};
				};
			};

			gpio@74 {
				compatible = "ti,tca9539";
				reg = <0x74>;
				gpio-controller;
				#gpio-cells = <0x02>;
				phandle = <0xdd>;

				audio-out-off-hog {
					gpio-hog;
					gpios = <0x00 0x00>;
					output-high;
					line-name = "Audio_Out_OFF";
				};

				hub-pwen-hog {
					gpio-hog;
					gpios = <0x06 0x00>;
					output-high;
					line-name = "HUB pwen";
				};

				hub-rst-hog {
					gpio-hog;
					gpios = <0x07 0x00>;
					output-high;
					line-name = "HUB rst";
				};

				otg-extlpn-hog {
					gpio-hog;
					gpios = <0x09 0x00>;
					output-high;
					line-name = "OTG EXTLPn";
				};

				otg-offvbusn-hog {
					gpio-hog;
					gpios = <0x08 0x00>;
					output-low;
					line-name = "OTG OFFVBUSn";
				};

				snd-rst-hog {
					gpio-hog;
					gpios = <0x0f 0x00>;
					output-high;
					line-name = "SND_RST";
				};
			};

			gpio@75 {
				compatible = "ti,tca9539";
				reg = <0x75>;
				gpio-controller;
				#gpio-cells = <0x02>;
				interrupt-controller;
				interrupt-parent = <0x2f>;
				interrupts = <0x04 0x02>;
				phandle = <0x28>;

				gps_rst {
					gpio-hog;
					gpios = <0x06 0x00>;
					output-high;
					line-name = "GPS rst";
				};

				fpdl_shdn {
					gpio-hog;
					gpios = <0x09 0x00>;
					output-high;
					line-name = "FPDLink shdn";
				};
			};
		};

		i2c@e66d0000 {
			#address-cells = <0x01>;
			#size-cells = <0x00>;
			compatible = "renesas,i2c-r8a7795\0renesas,rcar-gen3-i2c";
			reg = <0x00 0xe66d0000 0x00 0x40>;
			interrupts = <0x00 0x122 0x04>;
			clocks = <0x0c 0x01 0x3a0>;
			power-domains = <0x09 0x20>;
			resets = <0x0c 0x3a0>;
			dmas = <0x30 0x97 0x30 0x96>;
			dma-names = "tx\0rx";
			i2c-scl-internal-delay-ns = <0x6e>;
			status = "disabled";
		};

		i2c@e66d8000 {
			#address-cells = <0x01>;
			#size-cells = <0x00>;
			compatible = "renesas,i2c-r8a7795\0renesas,rcar-gen3-i2c";
			reg = <0x00 0xe66d8000 0x00 0x40>;
			interrupts = <0x00 0x13 0x04>;
			clocks = <0x0c 0x01 0x39f>;
			power-domains = <0x09 0x20>;
			resets = <0x0c 0x39f>;
			dmas = <0x30 0x99 0x30 0x98>;
			dma-names = "tx\0rx";
			i2c-scl-internal-delay-ns = <0x6e>;
			status = "okay";
			clock-frequency = <0x61a80>;

			clock-generator@6a {
				compatible = "idt,5p49v5925";
				reg = <0x6a>;
				#clock-cells = <0x01>;
				clocks = <0x31>;
				clock-names = "xin";
				phandle = <0xc6>;
			};

			i2c-switch@71 {
				compatible = "nxp,pca9548";
				#address-cells = <0x01>;
				#size-cells = <0x00>;
				reg = <0x71>;
				reset-gpios = <0x32 0x0f 0x01>;

				i2c@0 {
					#address-cells = <0x01>;
					#size-cells = <0x00>;
					reg = <0x00>;
				};

				i2c@1 {
					#address-cells = <0x01>;
					#size-cells = <0x00>;
					reg = <0x01>;

					deser@2c {
						compatible = "maxim,max9286\0ti,ub9x4";
						#address-cells = <0x01>;
						#size-cells = <0x00>;
						reg = <0x2c 0x3a>;
						reg-names = "max9286\0ub9x4";
						regs = <0x0c 0x0d 0x0e 0x0f>;
						shutdown-gpios = <0x33 0x0d 0x01>;
						poc0-supply = <0x34>;
						poc1-supply = <0x35>;
						poc2-supply = <0x36>;
						poc3-supply = <0x37>;

						ports {
							#address-cells = <0x01>;
							#size-cells = <0x00>;

							port@0 {
								reg = <0x00>;

								endpoint {
									remote-endpoint = <0x38>;
									phandle = <0x3d>;
								};
							};

							port@1 {
								reg = <0x01>;

								endpoint {
									remote-endpoint = <0x39>;
									phandle = <0x3e>;
								};
							};

							port@2 {
								reg = <0x02>;

								endpoint {
									remote-endpoint = <0x3a>;
									phandle = <0x3f>;
								};
							};

							port@3 {
								reg = <0x03>;

								endpoint {
									remote-endpoint = <0x3b>;
									phandle = <0x40>;
								};
							};

							port@4 {
								reg = <0x04>;

								endpoint {
									clock-lanes = <0x00>;
									data-lanes = <0x01 0x02 0x03 0x04>;
									remote-endpoint = <0x3c>;
									phandle = <0xba>;
								};
							};
						};

						i2c@0 {
							#address-cells = <0x01>;
							#size-cells = <0x00>;
							reg = <0x00>;

							camera@60 {
								compatible = "onnn,ap0101\0onnn,ap0201\0ovti,ov10635\0ovti,ov2311\0ovti,ov490\0ovti,ov495\0sony,isx016\0sony,isx019\0dummy,camera";
								reg = <0x60 0x0c>;

								port {

									endpoint {
										remote-endpoint = <0x3d>;
										phandle = <0x38>;
									};
								};
							};
						};

						i2c@1 {
							#address-cells = <0x01>;
							#size-cells = <0x00>;
							reg = <0x01>;

							camera@61 {
								compatible = "onnn,ap0101\0onnn,ap0201\0ovti,ov10635\0ovti,ov2311\0ovti,ov490\0ovti,ov495\0sony,isx016\0sony,isx019\0dummy,camera";
								reg = <0x61 0x0d>;

								port {

									endpoint {
										remote-endpoint = <0x3e>;
										phandle = <0x39>;
									};
								};
							};
						};

						i2c@2 {
							#address-cells = <0x01>;
							#size-cells = <0x00>;
							reg = <0x02>;

							camera@62 {
								compatible = "onnn,ap0101\0onnn,ap0201\0ovti,ov10635\0ovti,ov2311\0ovti,ov490\0ovti,ov495\0sony,isx016\0sony,isx019\0dummy,camera";
								reg = <0x62 0x0e>;

								port {

									endpoint {
										remote-endpoint = <0x3f>;
										phandle = <0x3a>;
									};
								};
							};
						};

						i2c@3 {
							#address-cells = <0x01>;
							#size-cells = <0x00>;
							reg = <0x03>;

							camera@63 {
								compatible = "onnn,ap0101\0onnn,ap0201\0ovti,ov10635\0ovti,ov2311\0ovti,ov490\0ovti,ov495\0sony,isx016\0sony,isx019\0dummy,camera";
								reg = <0x63 0x0f>;

								port {

									endpoint {
										remote-endpoint = <0x40>;
										phandle = <0x3b>;
									};
								};
							};
						};
					};
				};

				i2c@3 {
					#address-cells = <0x01>;
					#size-cells = <0x00>;
					reg = <0x03>;
				};

				i2c@4 {
					#address-cells = <0x01>;
					#size-cells = <0x00>;
					reg = <0x04>;

					ov5647@36 {
						compatible = "ovti,ov5647";
						reg = <0x36>;
						clocks = <0x41>;

						port@0 {

							endpoint {
								clock-lanes = <0x00>;
								data-lanes = <0x01 0x02>;
								remote-endpoint = <0x42>;
								phandle = <0xb1>;
							};
						};
					};
				};

				i2c@5 {
					#address-cells = <0x01>;
					#size-cells = <0x00>;
					reg = <0x05>;

					ov5642@3c {
						compatible = "ovti,ov5642";
						reg = <0x3c>;
						clocks = <0x41>;
						clock-names = "mclk";

						port@0 {

							endpoint {
								remote-endpoint = <0x43>;
								phandle = <0x6a>;
							};
						};
					};
				};

				i2c@7 {
					#address-cells = <0x01>;
					#size-cells = <0x00>;
					reg = <0x07>;

					gpio@5c {
						compatible = "maxim,max7325";
						reg = <0x5c>;
						gpio-controller;
						#gpio-cells = <0x02>;
						phandle = <0x33>;

						video_a_des_cfg2 {
							gpio-hog;
							gpios = <0x04 0x00>;
							input;
							line-name = "Video-A cfg2";
						};

						video_a_des_cfg1 {
							gpio-hog;
							gpios = <0x06 0x00>;
							input;
							line-name = "Video-A cfg1";
						};

						video_a_des_cfg0 {
							gpio-hog;
							gpios = <0x07 0x00>;
							input;
							line-name = "Video-A cfg0";
						};

						video_a_pwr_shdn {
							gpio-hog;
							gpios = <0x0e 0x00>;
							output-high;
							line-name = "Video-A PWR_SHDN";
						};

						video_a_led {
							gpio-hog;
							gpios = <0x0c 0x00>;
							output-low;
							line-name = "Video-A LED";
						};
					};
				};
			};

			gpio@76 {
				compatible = "ti,tca9539";
				reg = <0x76>;
				gpio-controller;
				#gpio-cells = <0x02>;
				interrupt-controller;
				interrupt-parent = <0x44>;
				interrupts = <0x03 0x02>;

				port_b_a0 {
					gpio-hog;
					gpios = <0x00 0x00>;
					output-low;
					line-name = "Video-B A0";
				};

				port_b_a1 {
					gpio-hog;
					gpios = <0x01 0x00>;
					output-high;
					line-name = "Video-B A1";
				};

				port_a_a0 {
					gpio-hog;
					gpios = <0x02 0x00>;
					output-low;
					line-name = "Video-A A0";
				};

				port_a_a1 {
					gpio-hog;
					gpios = <0x03 0x00>;
					output-high;
					line-name = "Video-A A1";
				};

				cmos_pwdn {
					gpio-hog;
					gpios = <0x08 0x00>;
					output-high;
					line-name = "CMOS PWDN";
				};

				cmos_rst {
					gpio-hog;
					gpios = <0x09 0x00>;
					output-high;
					line-name = "CMOS RST";
				};

				rpi_cam_io_1 {
					gpio-hog;
					gpios = <0x0a 0x00>;
					output-high;
					line-name = "RaspB_IO1";
				};

				rpi_cam_io_0 {
					gpio-hog;
					gpios = <0x0b 0x00>;
					output-high;
					line-name = "RaspB_IO0";
				};

				sam_rst {
					gpio-hog;
					gpios = <0x04 0x00>;
					output-high;
					line-name = "SAM RST";
				};

				sam_pwr {
					gpio-hog;
					gpios = <0x05 0x00>;
					output-low;
					line-name = "SAM PWR";
				};

				lvds_vs_fpdl {
					gpio-hog;
					gpios = <0x0e 0x00>;
					output-high;
					line-name = "LVDS switch";
				};
			};

			gpio@77 {
				compatible = "ti,tca9539";
				reg = <0x77>;
				gpio-controller;
				#gpio-cells = <0x02>;
				phandle = <0xde>;

				mpcie_wake {
					gpio-hog;
					gpios = <0x00 0x00>;
					output-low;
					line-name = "mPCIe WAKE#";
				};

				mpcie_wdisable {
					gpio-hog;
					gpios = <0x01 0x00>;
					output-high;
					line-name = "mPCIe W_DISABLE";
				};

				mpcie_clreq {
					gpio-hog;
					gpios = <0x02 0x00>;
					input;
					line-name = "mPCIe CLKREQ#";
				};

				mpcie_ovc {
					gpio-hog;
					gpios = <0x03 0x00>;
					input;
					line-name = "mPCIe OVC";
				};
			};
		};

		i2c@e66e0000 {
			#address-cells = <0x01>;
			#size-cells = <0x00>;
			compatible = "renesas,i2c-r8a7795\0renesas,rcar-gen3-i2c";
			reg = <0x00 0xe66e0000 0x00 0x40>;
			interrupts = <0x00 0x14 0x04>;
			clocks = <0x0c 0x01 0x397>;
			power-domains = <0x09 0x20>;
			resets = <0x0c 0x397>;
			dmas = <0x30 0x9b 0x30 0x9a>;
			dma-names = "tx\0rx";
			i2c-scl-internal-delay-ns = <0x6e>;
			status = "disabled";
		};

		i2c@e66e8000 {
			#address-cells = <0x01>;
			#size-cells = <0x00>;
			compatible = "renesas,i2c-r8a7795\0renesas,rcar-gen3-i2c";
			reg = <0x00 0xe66e8000 0x00 0x40>;
			interrupts = <0x00 0x15 0x04>;
			clocks = <0x0c 0x01 0x396>;
			power-domains = <0x09 0x20>;
			resets = <0x0c 0x396>;
			dmas = <0x30 0x9d 0x30 0x9c>;
			dma-names = "tx\0rx";
			i2c-scl-internal-delay-ns = <0x06>;
			status = "disabled";
		};

		i2c@e60b0000 {
			#address-cells = <0x01>;
			#size-cells = <0x00>;
			compatible = "renesas,iic-r8a7795\0renesas,rcar-gen3-iic\0renesas,rmobile-iic";
			reg = <0x00 0xe60b0000 0x00 0x425>;
			interrupts = <0x00 0xad 0x04>;
			clocks = <0x0c 0x01 0x39e>;
			power-domains = <0x09 0x20>;
			resets = <0x0c 0x39e>;
			dmas = <0x30 0x11 0x30 0x10>;
			dma-names = "tx\0rx";
			status = "okay";
			clock-frequency = <0x61a80>;

			pmic@30 {
				pinctrl-0 = <0x45>;
				pinctrl-names = "default";
				compatible = "rohm,bd9571mwv";
				reg = <0x30>;
				interrupt-parent = <0x46>;
				interrupts = <0x00 0x08>;
				interrupt-controller;
				#interrupt-cells = <0x02>;
				gpio-controller;
				#gpio-cells = <0x02>;
				rohm,ddr-backup-power = <0x0f>;
				rohm,rstbmode-pulse;

				regulators {

					dvfs {
						regulator-name = "dvfs";
						regulator-min-microvolt = <0xb71b0>;
						regulator-max-microvolt = <0xfb770>;
						regulator-boot-on;
						regulator-always-on;
						phandle = <0x15>;
					};
				};
			};
		};

		serial@e6540000 {
			compatible = "renesas,hscif-r8a7795\0renesas,rcar-gen3-hscif\0renesas,hscif";
			reg = <0x00 0xe6540000 0x00 0x60>;
			interrupts = <0x00 0x9a 0x04>;
			clocks = <0x0c 0x01 0x208 0x0c 0x00 0x10 0x47>;
			clock-names = "fck\0brg_int\0scif_clk";
			dmas = <0x1f 0x31 0x1f 0x30 0x20 0x31 0x20 0x30>;
			dma-names = "tx\0rx\0tx\0rx";
			power-domains = <0x09 0x20>;
			resets = <0x0c 0x208>;
			status = "okay";
			pinctrl-0 = <0x48>;
			pinctrl-names = "default";
			uart-has-rtscts;
		};

		serial@e6550000 {
			compatible = "renesas,hscif-r8a7795\0renesas,rcar-gen3-hscif\0renesas,hscif";
			reg = <0x00 0xe6550000 0x00 0x60>;
			interrupts = <0x00 0x9b 0x04>;
			clocks = <0x0c 0x01 0x207 0x0c 0x00 0x10 0x47>;
			clock-names = "fck\0brg_int\0scif_clk";
			dmas = <0x1f 0x33 0x1f 0x32 0x20 0x33 0x20 0x32>;
			dma-names = "tx\0rx\0tx\0rx";
			power-domains = <0x09 0x20>;
			resets = <0x0c 0x207>;
			status = "okay";
			pinctrl-0 = <0x49>;
			pinctrl-names = "default";
		};

		serial@e6560000 {
			compatible = "renesas,hscif-r8a7795\0renesas,rcar-gen3-hscif\0renesas,hscif";
			reg = <0x00 0xe6560000 0x00 0x60>;
			interrupts = <0x00 0x90 0x04>;
			clocks = <0x0c 0x01 0x206 0x0c 0x00 0x10 0x47>;
			clock-names = "fck\0brg_int\0scif_clk";
			dmas = <0x1f 0x35 0x1f 0x34 0x20 0x35 0x20 0x34>;
			dma-names = "tx\0rx\0tx\0rx";
			power-domains = <0x09 0x20>;
			resets = <0x0c 0x206>;
			status = "disabled";
		};

		serial@e66a0000 {
			compatible = "renesas,hscif-r8a7795\0renesas,rcar-gen3-hscif\0renesas,hscif";
			reg = <0x00 0xe66a0000 0x00 0x60>;
			interrupts = <0x00 0x91 0x04>;
			clocks = <0x0c 0x01 0x205 0x0c 0x00 0x10 0x47>;
			clock-names = "fck\0brg_int\0scif_clk";
			dmas = <0x30 0x37 0x30 0x36>;
			dma-names = "tx\0rx";
			power-domains = <0x09 0x20>;
			resets = <0x0c 0x205>;
			status = "disabled";
		};

		serial@e66b0000 {
			compatible = "renesas,hscif-r8a7795\0renesas,rcar-gen3-hscif\0renesas,hscif";
			reg = <0x00 0xe66b0000 0x00 0x60>;
			interrupts = <0x00 0x92 0x04>;
			clocks = <0x0c 0x01 0x204 0x0c 0x00 0x10 0x47>;
			clock-names = "fck\0brg_int\0scif_clk";
			dmas = <0x30 0x39 0x30 0x38>;
			dma-names = "tx\0rx";
			power-domains = <0x09 0x20>;
			resets = <0x0c 0x204>;
			status = "disabled";
		};

		usb@e6590000 {
			compatible = "renesas,usbhs-r8a7795\0renesas,rcar-gen3-usbhs";
			reg = <0x00 0xe6590000 0x00 0x200>;
			interrupts = <0x00 0x6b 0x04>;
			clocks = <0x0c 0x01 0x2c0 0x0c 0x01 0x2bf>;
			dmas = <0x4a 0x00 0x4a 0x01 0x4b 0x00 0x4b 0x01>;
			dma-names = "ch0\0ch1\0ch2\0ch3";
			renesas,buswait = <0x0b>;
			phys = <0x4c 0x03>;
			phy-names = "usb";
			power-domains = <0x09 0x20>;
			resets = <0x0c 0x2c0 0x0c 0x2bf>;
			status = "okay";
			dr_mode = "otg";
		};

		usb@e659c000 {
			compatible = "renesas,usbhs-r8a7795\0renesas,rcar-gen3-usbhs";
			reg = <0x00 0xe659c000 0x00 0x200>;
			interrupts = <0x00 0x25 0x04>;
			clocks = <0x0c 0x01 0x2c1 0x0c 0x01 0x2bc>;
			dmas = <0x4d 0x00 0x4d 0x01 0x4e 0x00 0x4e 0x01>;
			dma-names = "ch0\0ch1\0ch2\0ch3";
			renesas,buswait = <0x0b>;
			phys = <0x4f 0x03>;
			phy-names = "usb";
			power-domains = <0x09 0x20>;
			resets = <0x0c 0x2c1 0x0c 0x2bc>;
			status = "disabled";
		};

		dma-controller@e65a0000 {
			compatible = "renesas,r8a7795-usb-dmac\0renesas,usb-dmac";
			reg = <0x00 0xe65a0000 0x00 0x100>;
			interrupts = <0x00 0x6d 0x04 0x00 0x6d 0x04>;
			interrupt-names = "ch0\0ch1";
			clocks = <0x0c 0x01 0x14a>;
			power-domains = <0x09 0x20>;
			resets = <0x0c 0x14a>;
			#dma-cells = <0x01>;
			dma-channels = <0x02>;
			phandle = <0x4a>;
		};

		dma-controller@e65b0000 {
			compatible = "renesas,r8a7795-usb-dmac\0renesas,usb-dmac";
			reg = <0x00 0xe65b0000 0x00 0x100>;
			interrupts = <0x00 0x6e 0x04 0x00 0x6e 0x04>;
			interrupt-names = "ch0\0ch1";
			clocks = <0x0c 0x01 0x14b>;
			power-domains = <0x09 0x20>;
			resets = <0x0c 0x14b>;
			#dma-cells = <0x01>;
			dma-channels = <0x02>;
			phandle = <0x4b>;
		};

		dma-controller@e6460000 {
			compatible = "renesas,r8a7795-usb-dmac\0renesas,usb-dmac";
			reg = <0x00 0xe6460000 0x00 0x100>;
			interrupts = <0x00 0x22 0x04 0x00 0x22 0x04>;
			interrupt-names = "ch0\0ch1";
			clocks = <0x0c 0x01 0x146>;
			power-domains = <0x09 0x20>;
			resets = <0x0c 0x146>;
			#dma-cells = <0x01>;
			dma-channels = <0x02>;
			phandle = <0x4d>;
		};

		dma-controller@e6470000 {
			compatible = "renesas,r8a7795-usb-dmac\0renesas,usb-dmac";
			reg = <0x00 0xe6470000 0x00 0x100>;
			interrupts = <0x00 0x23 0x04 0x00 0x23 0x04>;
			interrupt-names = "ch0\0ch1";
			clocks = <0x0c 0x01 0x149>;
			power-domains = <0x09 0x20>;
			resets = <0x0c 0x149>;
			#dma-cells = <0x01>;
			dma-channels = <0x02>;
			phandle = <0x4e>;
		};

		usb-phy@e65ee000 {
			compatible = "renesas,r8a7795-usb3-phy\0renesas,rcar-gen3-usb3-phy";
			reg = <0x00 0xe65ee000 0x00 0x90>;
			clocks = <0x0c 0x01 0x148 0x50 0x51>;
			clock-names = "usb3-if\0usb3s_clk\0usb_extal";
			power-domains = <0x09 0x20>;
			resets = <0x0c 0x148>;
			#phy-cells = <0x00>;
			status = "disabled";
		};

		crypto@e6601000 {
			compatible = "arm,cryptocell-630p-ree";
			interrupts = <0x00 0x47 0x04>;
			reg = <0x00 0xe6601000 0x00 0x1000>;
			power-domains = <0x09 0x20>;
		};

		dma-controller@e6700000 {
			compatible = "renesas,dmac-r8a7795\0renesas,rcar-dmac";
			reg = <0x00 0xe6700000 0x00 0x10000>;
			interrupts = <0x00 0xc7 0x04 0x00 0xc8 0x04 0x00 0xc9 0x04 0x00 0xca 0x04 0x00 0xcb 0x04 0x00 0xcc 0x04 0x00 0xcd 0x04 0x00 0xce 0x04 0x00 0xcf 0x04 0x00 0xd0 0x04 0x00 0xd1 0x04 0x00 0xd2 0x04 0x00 0xd3 0x04 0x00 0xd4 0x04 0x00 0xd5 0x04 0x00 0xd6 0x04 0x00 0xd7 0x04>;
			interrupt-names = "error\0ch0\0ch1\0ch2\0ch3\0ch4\0ch5\0ch6\0ch7\0ch8\0ch9\0ch10\0ch11\0ch12\0ch13\0ch14\0ch15";
			clocks = <0x0c 0x01 0xdb>;
			clock-names = "fck";
			power-domains = <0x09 0x20>;
			resets = <0x0c 0xdb>;
			#dma-cells = <0x01>;
			dma-channels = <0x10>;
			phandle = <0x30>;
		};

		dma-controller@e7300000 {
			compatible = "renesas,dmac-r8a7795\0renesas,rcar-dmac";
			reg = <0x00 0xe7300000 0x00 0x10000>;
			interrupts = <0x00 0xdc 0x04 0x00 0xd8 0x04 0x00 0xd9 0x04 0x00 0xda 0x04 0x00 0xdb 0x04 0x00 0x134 0x04 0x00 0x135 0x04 0x00 0x136 0x04 0x00 0x137 0x04 0x00 0x138 0x04 0x00 0x139 0x04 0x00 0x13a 0x04 0x00 0x13b 0x04 0x00 0x13c 0x04 0x00 0x13d 0x04 0x00 0x13e 0x04 0x00 0x13f 0x04>;
			interrupt-names = "error\0ch0\0ch1\0ch2\0ch3\0ch4\0ch5\0ch6\0ch7\0ch8\0ch9\0ch10\0ch11\0ch12\0ch13\0ch14\0ch15";
			clocks = <0x0c 0x01 0xda>;
			clock-names = "fck";
			power-domains = <0x09 0x20>;
			resets = <0x0c 0xda>;
			#dma-cells = <0x01>;
			dma-channels = <0x10>;
			phandle = <0x1f>;
		};

		dma-controller@e7310000 {
			compatible = "renesas,dmac-r8a7795\0renesas,rcar-dmac";
			reg = <0x00 0xe7310000 0x00 0x10000>;
			interrupts = <0x00 0x1a0 0x04 0x00 0x1a1 0x04 0x00 0x1a2 0x04 0x00 0x1a3 0x04 0x00 0x1a4 0x04 0x00 0x1a5 0x04 0x00 0x1a6 0x04 0x00 0x1a7 0x04 0x00 0x1a8 0x04 0x00 0x1a9 0x04 0x00 0x1aa 0x04 0x00 0x1ab 0x04 0x00 0x1ac 0x04 0x00 0x1ad 0x04 0x00 0x1ae 0x04 0x00 0x1af 0x04 0x00 0x18d 0x04>;
			interrupt-names = "error\0ch0\0ch1\0ch2\0ch3\0ch4\0ch5\0ch6\0ch7\0ch8\0ch9\0ch10\0ch11\0ch12\0ch13\0ch14\0ch15";
			clocks = <0x0c 0x01 0xd9>;
			clock-names = "fck";
			power-domains = <0x09 0x20>;
			resets = <0x0c 0xd9>;
			#dma-cells = <0x01>;
			dma-channels = <0x10>;
			phandle = <0x20>;
		};

		iommu@e67b0000 {
			compatible = "renesas,ipmmu-r8a7795";
			reg = <0x00 0xe67b0000 0x00 0x1000>;
			interrupts = <0x00 0xc4 0x04 0x00 0xc5 0x04>;
			power-domains = <0x09 0x20>;
			#iommu-cells = <0x01>;
			phandle = <0x52>;
		};

		iommu@e6740000 {
			compatible = "renesas,ipmmu-r8a7795";
			reg = <0x00 0xe6740000 0x00 0x1000>;
			renesas,ipmmu-main = <0x52 0x00>;
			power-domains = <0x09 0x20>;
			#iommu-cells = <0x01>;
			status = "disabled";
		};

		iommu@e7740000 {
			compatible = "renesas,ipmmu-r8a7795";
			reg = <0x00 0xe7740000 0x00 0x1000>;
			renesas,ipmmu-main = <0x52 0x01>;
			power-domains = <0x09 0x20>;
			#iommu-cells = <0x01>;
			phandle = <0x9d>;
		};

		iommu@e6570000 {
			compatible = "renesas,ipmmu-r8a7795";
			reg = <0x00 0xe6570000 0x00 0x1000>;
			renesas,ipmmu-main = <0x52 0x02>;
			power-domains = <0x09 0x20>;
			#iommu-cells = <0x01>;
			status = "disabled";
		};

		iommu@ff8b0000 {
			compatible = "renesas,ipmmu-r8a7795";
			reg = <0x00 0xff8b0000 0x00 0x1000>;
			renesas,ipmmu-main = <0x52 0x03>;
			power-domains = <0x09 0x18>;
			#iommu-cells = <0x01>;
			status = "disabled";
		};

		iommu@ec670000 {
			compatible = "renesas,ipmmu-r8a7795";
			reg = <0x00 0xec670000 0x00 0x1000>;
			renesas,ipmmu-main = <0x52 0x04>;
			power-domains = <0x09 0x20>;
			#iommu-cells = <0x01>;
			status = "disabled";
		};

		iommu@fd800000 {
			compatible = "renesas,ipmmu-r8a7795";
			reg = <0x00 0xfd800000 0x00 0x1000>;
			renesas,ipmmu-main = <0x52 0x06>;
			power-domains = <0x09 0x20>;
			#iommu-cells = <0x01>;
			status = "disabled";
		};

		iommu@fd950000 {
			compatible = "renesas,ipmmu-r8a7795";
			reg = <0x00 0xfd950000 0x00 0x1000>;
			renesas,ipmmu-main = <0x52 0x07>;
			power-domains = <0x09 0x20>;
			#iommu-cells = <0x01>;
			status = "disabled";
		};

		iommu@fd960000 {
			compatible = "renesas,ipmmu-r8a7795";
			reg = <0x00 0xfd960000 0x00 0x1000>;
			renesas,ipmmu-main = <0x52 0x08>;
			power-domains = <0x09 0x20>;
			#iommu-cells = <0x01>;
			status = "disabled";
		};

		iommu@fd970000 {
			compatible = "renesas,ipmmu-r8a7795";
			reg = <0x00 0xfd970000 0x00 0x1000>;
			renesas,ipmmu-main = <0x52 0x09>;
			power-domains = <0x09 0x20>;
			#iommu-cells = <0x01>;
			status = "disabled";
		};

		iommu@ffc80000 {
			compatible = "renesas,ipmmu-r8a7795";
			reg = <0x00 0xffc80000 0x00 0x1000>;
			renesas,ipmmu-main = <0x52 0x0a>;
			power-domains = <0x09 0x20>;
			#iommu-cells = <0x01>;
			status = "disabled";
		};

		iommu@fe6b0000 {
			compatible = "renesas,ipmmu-mmu-r8a7795";
			reg = <0x00 0xfe6b0000 0x00 0x1000>;
			renesas,ipmmu-main = <0x52 0x0c>;
			power-domains = <0x09 0x0e>;
			#iommu-cells = <0x01>;
			status = "disabled";
		};

		iommu@fe6f0000 {
			compatible = "renesas,ipmmu-mmu-r8a7795";
			reg = <0x00 0xfe6f0000 0x00 0x1000>;
			renesas,ipmmu-main = <0x52 0x0d>;
			power-domains = <0x09 0x0e>;
			#iommu-cells = <0x01>;
			status = "disabled";
		};

		iommu@febd0000 {
			compatible = "renesas,ipmmu-r8a7795";
			reg = <0x00 0xfebd0000 0x00 0x1000>;
			renesas,ipmmu-main = <0x52 0x0e>;
			power-domains = <0x09 0x20>;
			#iommu-cells = <0x01>;
		};

		iommu@febe0000 {
			compatible = "renesas,ipmmu-r8a7795";
			reg = <0x00 0xfebe0000 0x00 0x1000>;
			renesas,ipmmu-main = <0x52 0x0f>;
			power-domains = <0x09 0x20>;
			#iommu-cells = <0x01>;
			status = "disabled";
		};

		iommu@fe990000 {
			compatible = "renesas,ipmmu-mmu-r8a7795";
			reg = <0x00 0xfe990000 0x00 0x1000>;
			renesas,ipmmu-main = <0x52 0x10>;
			power-domains = <0x09 0x09>;
			#iommu-cells = <0x01>;
			status = "disabled";
		};

		iommu@fe980000 {
			compatible = "renesas,ipmmu-mmu-r8a7795";
			reg = <0x00 0xfe980000 0x00 0x1000>;
			renesas,ipmmu-main = <0x52 0x11>;
			power-domains = <0x09 0x09>;
			#iommu-cells = <0x01>;
		};

		qos@e67e0000 {
			compatible = "renesas,qos";
			reg = <0x00 0xe67e0000 0x00 0x10090>;
		};

		ethernet@e6800000 {
			compatible = "renesas,etheravb-r8a7795\0renesas,etheravb-rcar-gen3";
			reg = <0x00 0xe6800000 0x00 0x800 0x00 0xe6a00000 0x00 0x10000>;
			interrupts = <0x00 0x27 0x04 0x00 0x28 0x04 0x00 0x29 0x04 0x00 0x2a 0x04 0x00 0x2b 0x04 0x00 0x2c 0x04 0x00 0x2d 0x04 0x00 0x2e 0x04 0x00 0x2f 0x04 0x00 0x30 0x04 0x00 0x31 0x04 0x00 0x32 0x04 0x00 0x33 0x04 0x00 0x34 0x04 0x00 0x35 0x04 0x00 0x36 0x04 0x00 0x37 0x04 0x00 0x38 0x04 0x00 0x39 0x04 0x00 0x3a 0x04 0x00 0x3b 0x04 0x00 0x3c 0x04 0x00 0x3d 0x04 0x00 0x3e 0x04 0x00 0x3f 0x04>;
			interrupt-names = "ch0\0ch1\0ch2\0ch3\0ch4\0ch5\0ch6\0ch7\0ch8\0ch9\0ch10\0ch11\0ch12\0ch13\0ch14\0ch15\0ch16\0ch17\0ch18\0ch19\0ch20\0ch21\0ch22\0ch23\0ch24";
			clocks = <0x0c 0x01 0x32c>;
			power-domains = <0x09 0x20>;
			resets = <0x0c 0x32c>;
			phy-mode = "rgmii";
			rx-internal-delay-ps = <0x00>;
			tx-internal-delay-ps = <0x7d0>;
			#address-cells = <0x01>;
			#size-cells = <0x00>;
			status = "okay";
			pinctrl-0 = <0x53>;
			pinctrl-names = "default";
			phy-handle = <0x54>;

			ethernet-phy@0 {
				rxc-skew-ps = <0x5dc>;
				reg = <0x00>;
				interrupt-parent = <0x55>;
				interrupts = <0x0b 0x08>;
				reset-gpios = <0x55 0x0a 0x01>;
				phandle = <0x54>;
			};
		};

		can@e6c30000 {
			compatible = "renesas,can-r8a7795\0renesas,rcar-gen3-can";
			reg = <0x00 0xe6c30000 0x00 0x1000>;
			interrupts = <0x00 0xba 0x04>;
			clocks = <0x0c 0x01 0x394 0x0c 0x00 0x27 0x56>;
			clock-names = "clkp1\0clkp2\0can_clk";
			assigned-clocks = <0x0c 0x00 0x27>;
			assigned-clock-rates = <0x2625a00>;
			power-domains = <0x09 0x20>;
			resets = <0x0c 0x394>;
			status = "disable";
			pinctrl-0 = <0x57>;
			pinctrl-names = "default";
		};

		can@e6c38000 {
			compatible = "renesas,can-r8a7795\0renesas,rcar-gen3-can";
			reg = <0x00 0xe6c38000 0x00 0x1000>;
			interrupts = <0x00 0xbb 0x04>;
			clocks = <0x0c 0x01 0x393 0x0c 0x00 0x27 0x56>;
			clock-names = "clkp1\0clkp2\0can_clk";
			assigned-clocks = <0x0c 0x00 0x27>;
			assigned-clock-rates = <0x2625a00>;
			power-domains = <0x09 0x20>;
			resets = <0x0c 0x393>;
			status = "disable";
			pinctrl-0 = <0x58>;
			pinctrl-names = "default";
		};

		can@e66c0000 {
			compatible = "renesas,r8a7795-canfd\0renesas,rcar-gen3-canfd";
			reg = <0x00 0xe66c0000 0x00 0x8000>;
			interrupts = <0x00 0x1d 0x04 0x00 0x1e 0x04>;
			clocks = <0x0c 0x01 0x392 0x0c 0x00 0x27 0x56>;
			clock-names = "fck\0canfd\0can_clk";
			assigned-clocks = <0x0c 0x00 0x27>;
			assigned-clock-rates = <0x2625a00>;
			power-domains = <0x09 0x20>;
			resets = <0x0c 0x392>;
			status = "okay";
			pinctrl-0 = <0x59 0x5a>;
			pinctrl-names = "default";

			channel0 {
				status = "okay";
			};

			channel1 {
				status = "okay";
			};
		};

		pwm@e6e30000 {
			compatible = "renesas,pwm-r8a7795\0renesas,pwm-rcar";
			reg = <0x00 0xe6e30000 0x00 0x08>;
			clocks = <0x0c 0x01 0x20b>;
			power-domains = <0x09 0x20>;
			resets = <0x0c 0x20b>;
			#pwm-cells = <0x02>;
			status = "disabled";
		};

		pwm@e6e31000 {
			compatible = "renesas,pwm-r8a7795\0renesas,pwm-rcar";
			reg = <0x00 0xe6e31000 0x00 0x08>;
			clocks = <0x0c 0x01 0x20b>;
			power-domains = <0x09 0x20>;
			resets = <0x0c 0x20b>;
			#pwm-cells = <0x02>;
			status = "disabled";
		};

		pwm@e6e32000 {
			compatible = "renesas,pwm-r8a7795\0renesas,pwm-rcar";
			reg = <0x00 0xe6e32000 0x00 0x08>;
			clocks = <0x0c 0x01 0x20b>;
			power-domains = <0x09 0x20>;
			resets = <0x0c 0x20b>;
			#pwm-cells = <0x02>;
			status = "disabled";
		};

		pwm@e6e33000 {
			compatible = "renesas,pwm-r8a7795\0renesas,pwm-rcar";
			reg = <0x00 0xe6e33000 0x00 0x08>;
			clocks = <0x0c 0x01 0x20b>;
			power-domains = <0x09 0x20>;
			resets = <0x0c 0x20b>;
			#pwm-cells = <0x02>;
			status = "disabled";
		};

		pwm@e6e34000 {
			compatible = "renesas,pwm-r8a7795\0renesas,pwm-rcar";
			reg = <0x00 0xe6e34000 0x00 0x08>;
			clocks = <0x0c 0x01 0x20b>;
			power-domains = <0x09 0x20>;
			resets = <0x0c 0x20b>;
			#pwm-cells = <0x02>;
			status = "disabled";
		};

		pwm@e6e35000 {
			compatible = "renesas,pwm-r8a7795\0renesas,pwm-rcar";
			reg = <0x00 0xe6e35000 0x00 0x08>;
			clocks = <0x0c 0x01 0x20b>;
			power-domains = <0x09 0x20>;
			resets = <0x0c 0x20b>;
			#pwm-cells = <0x02>;
			status = "disabled";
		};

		pwm@e6e36000 {
			compatible = "renesas,pwm-r8a7795\0renesas,pwm-rcar";
			reg = <0x00 0xe6e36000 0x00 0x08>;
			clocks = <0x0c 0x01 0x20b>;
			power-domains = <0x09 0x20>;
			resets = <0x0c 0x20b>;
			#pwm-cells = <0x02>;
			status = "disabled";
		};

		serial@e6e60000 {
			compatible = "renesas,scif-r8a7795\0renesas,rcar-gen3-scif\0renesas,scif";
			reg = <0x00 0xe6e60000 0x00 0x40>;
			interrupts = <0x00 0x98 0x04>;
			clocks = <0x0c 0x01 0xcf 0x0c 0x00 0x10 0x47>;
			clock-names = "fck\0brg_int\0scif_clk";
			dmas = <0x1f 0x51 0x1f 0x50 0x20 0x51 0x20 0x50>;
			dma-names = "tx\0rx\0tx\0rx";
			power-domains = <0x09 0x20>;
			resets = <0x0c 0xcf>;
			status = "disabled";
		};

		serial@e6e68000 {
			compatible = "renesas,scif-r8a7795\0renesas,rcar-gen3-scif\0renesas,scif";
			reg = <0x00 0xe6e68000 0x00 0x40>;
			interrupts = <0x00 0x99 0x04>;
			clocks = <0x0c 0x01 0xce 0x0c 0x00 0x10 0x47>;
			clock-names = "fck\0brg_int\0scif_clk";
			dmas = <0x1f 0x53 0x1f 0x52 0x20 0x53 0x20 0x52>;
			dma-names = "tx\0rx\0tx\0rx";
			power-domains = <0x09 0x20>;
			resets = <0x0c 0xce>;
			status = "okay";
			pinctrl-0 = <0x5b>;
			pinctrl-names = "default";
		};

		serial@e6e88000 {
			compatible = "renesas,scif-r8a7795\0renesas,rcar-gen3-scif\0renesas,scif";
			reg = <0x00 0xe6e88000 0x00 0x40>;
			interrupts = <0x00 0xa4 0x04>;
			clocks = <0x0c 0x01 0x136 0x0c 0x00 0x10 0x47>;
			clock-names = "fck\0brg_int\0scif_clk";
			power-domains = <0x09 0x20>;
			resets = <0x0c 0x136>;
			status = "okay";
			pinctrl-0 = <0x5c>;
			pinctrl-names = "default";
		};

		serial@e6c50000 {
			compatible = "renesas,scif-r8a7795\0renesas,rcar-gen3-scif\0renesas,scif";
			reg = <0x00 0xe6c50000 0x00 0x40>;
			interrupts = <0x00 0x17 0x04>;
			clocks = <0x0c 0x01 0xcc 0x0c 0x00 0x10 0x47>;
			clock-names = "fck\0brg_int\0scif_clk";
			dmas = <0x30 0x57 0x30 0x56>;
			dma-names = "tx\0rx";
			power-domains = <0x09 0x20>;
			resets = <0x0c 0xcc>;
			status = "disabled";
		};

		serial@e6c40000 {
			compatible = "renesas,scif-r8a7795\0renesas,rcar-gen3-scif\0renesas,scif";
			reg = <0x00 0xe6c40000 0x00 0x40>;
			interrupts = <0x00 0x10 0x04>;
			clocks = <0x0c 0x01 0xcb 0x0c 0x00 0x10 0x47>;
			clock-names = "fck\0brg_int\0scif_clk";
			dmas = <0x30 0x59 0x30 0x58>;
			dma-names = "tx\0rx";
			power-domains = <0x09 0x20>;
			resets = <0x0c 0xcb>;
			status = "disabled";
		};

		serial@e6f30000 {
			compatible = "renesas,scif-r8a7795\0renesas,rcar-gen3-scif\0renesas,scif";
			reg = <0x00 0xe6f30000 0x00 0x40>;
			interrupts = <0x00 0x11 0x04>;
			clocks = <0x0c 0x01 0xca 0x0c 0x00 0x10 0x47>;
			clock-names = "fck\0brg_int\0scif_clk";
			dmas = <0x1f 0x5b 0x1f 0x5a 0x20 0x5b 0x20 0x5a>;
			dma-names = "tx\0rx\0tx\0rx";
			power-domains = <0x09 0x20>;
			resets = <0x0c 0xca>;
			status = "disabled";
		};

		pwm@e6e80000 {
			compatible = "renesas,tpu-r8a7795\0renesas,tpu";
			reg = <0x00 0xe6e80000 0x00 0x148>;
			interrupts = <0x00 0x87 0x04>;
			clocks = <0x0c 0x01 0x130>;
			power-domains = <0x09 0x20>;
			resets = <0x0c 0x130>;
			#pwm-cells = <0x03>;
			status = "disabled";
		};

		mlp@ec520000 {
			compatible = "rcar,medialb-dim2";
			reg = <0x00 0xec520000 0x00 0x800>;
			interrupts = <0x00 0x180 0x04 0x00 0x181 0x04 0x00 0x182 0x04 0x00 0x183 0x04 0x00 0x184 0x04>;
			clocks = <0x0c 0x01 0x322>;
			power-domains = <0x09 0x20>;
			status = "disabled";
		};

		spi@e6e90000 {
			compatible = "renesas,msiof-r8a7795\0renesas,rcar-gen3-msiof";
			reg = <0x00 0xe6e90000 0x00 0x64>;
			interrupts = <0x00 0x9c 0x04>;
			clocks = <0x0c 0x01 0xd3 0x0c 0x00 0x26>;
			clock-names = "msiof_clk\0mso";
			assigned-clocks = <0x0c 0x00 0x26>;
			assigned-clock-rates = <0x1312d00>;
			dmas = <0x1f 0x41 0x1f 0x40 0x20 0x41 0x20 0x40>;
			dma-names = "tx\0rx\0tx\0rx";
			power-domains = <0x09 0x20>;
			resets = <0x0c 0xd3>;
			#address-cells = <0x01>;
			#size-cells = <0x00>;
			status = "disabled";
		};

		spi@e6ea0000 {
			compatible = "renesas,msiof-r8a7795\0renesas,rcar-gen3-msiof";
			reg = <0x00 0xe6ea0000 0x00 0x64>;
			interrupts = <0x00 0x9d 0x04>;
			clocks = <0x0c 0x01 0xd2 0x0c 0x00 0x26>;
			clock-names = "msiof_clk\0mso";
			assigned-clocks = <0x0c 0x00 0x26>;
			assigned-clock-rates = <0x1312d00>;
			dmas = <0x1f 0x43 0x1f 0x42 0x20 0x43 0x20 0x42>;
			dma-names = "tx\0rx\0tx\0rx";
			power-domains = <0x09 0x20>;
			resets = <0x0c 0xd2>;
			#address-cells = <0x01>;
			#size-cells = <0x00>;
			status = "disabled";
		};

		spi@e6c00000 {
			compatible = "renesas,msiof-r8a7795\0renesas,rcar-gen3-msiof";
			reg = <0x00 0xe6c00000 0x00 0x64>;
			interrupts = <0x00 0x9e 0x04>;
			clocks = <0x0c 0x01 0xd1 0x0c 0x00 0x26>;
			clock-names = "msiof_clk\0mso";
			assigned-clocks = <0x0c 0x00 0x26>;
			assigned-clock-rates = <0x1312d00>;
			dmas = <0x30 0x45 0x30 0x44>;
			dma-names = "tx\0rx";
			power-domains = <0x09 0x20>;
			resets = <0x0c 0xd1>;
			#address-cells = <0x01>;
			#size-cells = <0x00>;
			status = "disabled";
		};

		spi@e6c10000 {
			compatible = "renesas,msiof-r8a7795\0renesas,rcar-gen3-msiof";
			reg = <0x00 0xe6c10000 0x00 0x64>;
			interrupts = <0x00 0x9f 0x04>;
			clocks = <0x0c 0x01 0xd0 0x0c 0x00 0x26>;
			clock-names = "msiof_clk\0mso";
			assigned-clocks = <0x0c 0x00 0x26>;
			assigned-clock-rates = <0x1312d00>;
			dmas = <0x30 0x47 0x30 0x46>;
			dma-names = "tx\0rx";
			power-domains = <0x09 0x20>;
			resets = <0x0c 0xd0>;
			#address-cells = <0x01>;
			#size-cells = <0x00>;
			status = "disabled";
		};

		video@e6ef0000 {
			compatible = "renesas,vin-r8a7795";
			reg = <0x00 0xe6ef0000 0x00 0x1000>;
			interrupts = <0x00 0xbc 0x04>;
			clocks = <0x0c 0x01 0x32b>;
			power-domains = <0x09 0x20>;
			resets = <0x0c 0x32b>;
			renesas,id = <0x00>;
			status = "okay";

			ports {
				#address-cells = <0x01>;
				#size-cells = <0x00>;

				port@1 {
					#address-cells = <0x01>;
					#size-cells = <0x00>;
					reg = <0x01>;

					endpoint@0 {
						reg = <0x00>;
						remote-endpoint = <0x5d>;
						phandle = <0xb2>;
					};

					endpoint@2 {
						reg = <0x02>;
						remote-endpoint = <0x5e>;
						phandle = <0xbb>;
					};
				};
			};
		};

		video@e6ef1000 {
			compatible = "renesas,vin-r8a7795";
			reg = <0x00 0xe6ef1000 0x00 0x1000>;
			interrupts = <0x00 0xbd 0x04>;
			clocks = <0x0c 0x01 0x32a>;
			power-domains = <0x09 0x20>;
			resets = <0x0c 0x32a>;
			renesas,id = <0x01>;
			status = "okay";

			ports {
				#address-cells = <0x01>;
				#size-cells = <0x00>;

				port@1 {
					#address-cells = <0x01>;
					#size-cells = <0x00>;
					reg = <0x01>;

					endpoint@0 {
						reg = <0x00>;
						remote-endpoint = <0x5f>;
						phandle = <0xb3>;
					};

					endpoint@2 {
						reg = <0x02>;
						remote-endpoint = <0x60>;
						phandle = <0xbc>;
					};
				};
			};
		};

		video@e6ef2000 {
			compatible = "renesas,vin-r8a7795";
			reg = <0x00 0xe6ef2000 0x00 0x1000>;
			interrupts = <0x00 0xbe 0x04>;
			clocks = <0x0c 0x01 0x329>;
			power-domains = <0x09 0x20>;
			resets = <0x0c 0x329>;
			renesas,id = <0x02>;
			status = "okay";

			ports {
				#address-cells = <0x01>;
				#size-cells = <0x00>;

				port@1 {
					#address-cells = <0x01>;
					#size-cells = <0x00>;
					reg = <0x01>;

					endpoint@0 {
						reg = <0x00>;
						remote-endpoint = <0x61>;
						phandle = <0xb4>;
					};

					endpoint@2 {
						reg = <0x02>;
						remote-endpoint = <0x62>;
						phandle = <0xbd>;
					};
				};
			};
		};

		video@e6ef3000 {
			compatible = "renesas,vin-r8a7795";
			reg = <0x00 0xe6ef3000 0x00 0x1000>;
			interrupts = <0x00 0xbf 0x04>;
			clocks = <0x0c 0x01 0x328>;
			power-domains = <0x09 0x20>;
			resets = <0x0c 0x328>;
			renesas,id = <0x03>;
			status = "okay";

			ports {
				#address-cells = <0x01>;
				#size-cells = <0x00>;

				port@1 {
					#address-cells = <0x01>;
					#size-cells = <0x00>;
					reg = <0x01>;

					endpoint@0 {
						reg = <0x00>;
						remote-endpoint = <0x63>;
						phandle = <0xb5>;
					};

					endpoint@2 {
						reg = <0x02>;
						remote-endpoint = <0x64>;
						phandle = <0xbe>;
					};
				};
			};
		};

		video@e6ef4000 {
			compatible = "renesas,vin-r8a7795";
			reg = <0x00 0xe6ef4000 0x00 0x1000>;
			interrupts = <0x00 0xae 0x04>;
			clocks = <0x0c 0x01 0x327>;
			power-domains = <0x09 0x20>;
			resets = <0x0c 0x327>;
			renesas,id = <0x04>;
			status = "okay";

			ports {
				#address-cells = <0x01>;
				#size-cells = <0x00>;

				port@1 {
					#address-cells = <0x01>;
					#size-cells = <0x00>;
					reg = <0x01>;

					endpoint@0 {
						reg = <0x00>;
						remote-endpoint = <0x65>;
						phandle = <0xb6>;
					};

					endpoint@3 {
						reg = <0x03>;
						remote-endpoint = <0x66>;
						phandle = <0xbf>;
					};
				};
			};
		};

		video@e6ef5000 {
			compatible = "renesas,vin-r8a7795";
			reg = <0x00 0xe6ef5000 0x00 0x1000>;
			interrupts = <0x00 0xaf 0x04>;
			clocks = <0x0c 0x01 0x326>;
			power-domains = <0x09 0x20>;
			resets = <0x0c 0x326>;
			renesas,id = <0x05>;
			status = "okay";
			pinctrl-0 = <0x67>;
			pinctrl-names = "default";

			ports {
				#address-cells = <0x01>;
				#size-cells = <0x00>;

				port@1 {
					#address-cells = <0x01>;
					#size-cells = <0x00>;
					reg = <0x01>;

					endpoint@0 {
						reg = <0x00>;
						remote-endpoint = <0x68>;
						phandle = <0xb7>;
					};

					endpoint@3 {
						reg = <0x03>;
						remote-endpoint = <0x69>;
						phandle = <0xc0>;
					};
				};

				port@0 {

					endpoint@0 {
						bus-width = <0x08>;
						vsync-active = <0x01>;
						hsync-active = <0x00>;
						data-enable-active = <0x00>;
						remote-endpoint = <0x6a>;
						phandle = <0x43>;
					};
				};
			};
		};

		video@e6ef6000 {
			compatible = "renesas,vin-r8a7795";
			reg = <0x00 0xe6ef6000 0x00 0x1000>;
			interrupts = <0x00 0xb0 0x04>;
			clocks = <0x0c 0x01 0x325>;
			power-domains = <0x09 0x20>;
			resets = <0x0c 0x325>;
			renesas,id = <0x06>;
			status = "disabled";

			ports {
				#address-cells = <0x01>;
				#size-cells = <0x00>;

				port@1 {
					#address-cells = <0x01>;
					#size-cells = <0x00>;
					reg = <0x01>;

					endpoint@0 {
						reg = <0x00>;
						remote-endpoint = <0x6b>;
						phandle = <0xb8>;
					};

					endpoint@3 {
						reg = <0x03>;
						remote-endpoint = <0x6c>;
						phandle = <0xc1>;
					};
				};
			};
		};

		video@e6ef7000 {
			compatible = "renesas,vin-r8a7795";
			reg = <0x00 0xe6ef7000 0x00 0x1000>;
			interrupts = <0x00 0xab 0x04>;
			clocks = <0x0c 0x01 0x324>;
			power-domains = <0x09 0x20>;
			resets = <0x0c 0x324>;
			renesas,id = <0x07>;
			status = "disabled";

			ports {
				#address-cells = <0x01>;
				#size-cells = <0x00>;

				port@1 {
					#address-cells = <0x01>;
					#size-cells = <0x00>;
					reg = <0x01>;

					endpoint@0 {
						reg = <0x00>;
						remote-endpoint = <0x6d>;
						phandle = <0xb9>;
					};

					endpoint@3 {
						reg = <0x03>;
						remote-endpoint = <0x6e>;
						phandle = <0xc2>;
					};
				};
			};
		};

		rif@e6f40000 {
			compatible = "renesas,r8a7795-drif\0renesas,rcar-gen3-drif";
			reg = <0x00 0xe6f40000 0x00 0x64>;
			interrupts = <0x00 0x0c 0x04>;
			clocks = <0x0c 0x01 0x203>;
			clock-names = "fck";
			dmas = <0x1f 0x20 0x20 0x20>;
			dma-names = "rx\0rx";
			power-domains = <0x09 0x20>;
			resets = <0x0c 0x203>;
			renesas,bonding = <0x6f>;
			status = "disabled";
			phandle = <0x70>;
		};

		rif@e6f50000 {
			compatible = "renesas,r8a7795-drif\0renesas,rcar-gen3-drif";
			reg = <0x00 0xe6f50000 0x00 0x64>;
			interrupts = <0x00 0x0d 0x04>;
			clocks = <0x0c 0x01 0x202>;
			clock-names = "fck";
			dmas = <0x1f 0x22 0x20 0x22>;
			dma-names = "rx\0rx";
			power-domains = <0x09 0x20>;
			resets = <0x0c 0x202>;
			renesas,bonding = <0x70>;
			status = "disabled";
			phandle = <0x6f>;
		};

		rif@e6f60000 {
			compatible = "renesas,r8a7795-drif\0renesas,rcar-gen3-drif";
			reg = <0x00 0xe6f60000 0x00 0x64>;
			interrupts = <0x00 0x0e 0x04>;
			clocks = <0x0c 0x01 0x201>;
			clock-names = "fck";
			dmas = <0x1f 0x24 0x20 0x24>;
			dma-names = "rx\0rx";
			power-domains = <0x09 0x20>;
			resets = <0x0c 0x201>;
			renesas,bonding = <0x71>;
			status = "disabled";
			phandle = <0x72>;
		};

		rif@e6f70000 {
			compatible = "renesas,r8a7795-drif\0renesas,rcar-gen3-drif";
			reg = <0x00 0xe6f70000 0x00 0x64>;
			interrupts = <0x00 0x0f 0x04>;
			clocks = <0x0c 0x01 0x200>;
			clock-names = "fck";
			dmas = <0x1f 0x26 0x20 0x26>;
			dma-names = "rx\0rx";
			power-domains = <0x09 0x20>;
			resets = <0x0c 0x200>;
			renesas,bonding = <0x72>;
			status = "disabled";
			phandle = <0x71>;
		};

		rif@e6f80000 {
			compatible = "renesas,r8a7795-drif\0renesas,rcar-gen3-drif";
			reg = <0x00 0xe6f80000 0x00 0x64>;
			interrupts = <0x00 0x18 0x04>;
			clocks = <0x0c 0x01 0x1ff>;
			clock-names = "fck";
			dmas = <0x1f 0x28 0x20 0x28>;
			dma-names = "rx\0rx";
			power-domains = <0x09 0x20>;
			resets = <0x0c 0x1ff>;
			renesas,bonding = <0x73>;
			status = "disabled";
			phandle = <0x74>;
		};

		rif@e6f90000 {
			compatible = "renesas,r8a7795-drif\0renesas,rcar-gen3-drif";
			reg = <0x00 0xe6f90000 0x00 0x64>;
			interrupts = <0x00 0x19 0x04>;
			clocks = <0x0c 0x01 0x1fe>;
			clock-names = "fck";
			dmas = <0x1f 0x2a 0x20 0x2a>;
			dma-names = "rx\0rx";
			power-domains = <0x09 0x20>;
			resets = <0x0c 0x1fe>;
			renesas,bonding = <0x74>;
			status = "disabled";
			phandle = <0x73>;
		};

		rif@e6fa0000 {
			compatible = "renesas,r8a7795-drif\0renesas,rcar-gen3-drif";
			reg = <0x00 0xe6fa0000 0x00 0x64>;
			interrupts = <0x00 0x1a 0x04>;
			clocks = <0x0c 0x01 0x1fd>;
			clock-names = "fck";
			dmas = <0x1f 0x2c 0x20 0x2c>;
			dma-names = "rx\0rx";
			power-domains = <0x09 0x20>;
			resets = <0x0c 0x1fd>;
			renesas,bonding = <0x75>;
			status = "disabled";
			phandle = <0x76>;
		};

		rif@e6fb0000 {
			compatible = "renesas,r8a7795-drif\0renesas,rcar-gen3-drif";
			reg = <0x00 0xe6fb0000 0x00 0x64>;
			interrupts = <0x00 0x1b 0x04>;
			clocks = <0x0c 0x01 0x1fc>;
			clock-names = "fck";
			dmas = <0x1f 0x2e 0x20 0x2e>;
			dma-names = "rx\0rx";
			power-domains = <0x09 0x20>;
			resets = <0x0c 0x1fc>;
			renesas,bonding = <0x76>;
			status = "disabled";
			phandle = <0x75>;
		};

		sound@ec500000 {
			compatible = "renesas,rcar_sound-r8a7795\0renesas,rcar_sound-gen3";
			reg = <0x00 0xec500000 0x00 0x1000 0x00 0xec5a0000 0x00 0x100 0x00 0xec540000 0x00 0x1000 0x00 0xec541000 0x00 0x280 0x00 0xec760000 0x00 0x200>;
			reg-names = "scu\0adg\0ssiu\0ssi\0audmapp";
			clocks = <0x0c 0x01 0x3ed 0x0c 0x01 0x3ee 0x0c 0x01 0x3ef 0x0c 0x01 0x3f0 0x0c 0x01 0x3f1 0x0c 0x01 0x3f2 0x0c 0x01 0x3f3 0x0c 0x01 0x3f4 0x0c 0x01 0x3f5 0x0c 0x01 0x3f6 0x0c 0x01 0x3f7 0x0c 0x01 0x3fe 0x0c 0x01 0x3ff 0x0c 0x01 0x400 0x0c 0x01 0x401 0x0c 0x01 0x402 0x0c 0x01 0x403 0x0c 0x01 0x404 0x0c 0x01 0x405 0x0c 0x01 0x406 0x0c 0x01 0x407 0x0c 0x01 0x3fc 0x0c 0x01 0x3fd 0x0c 0x01 0x3fc 0x0c 0x01 0x3fd 0x0c 0x01 0x3fb 0x0c 0x01 0x3fa 0x77 0x26 0x78 0x0c 0x00 0x09>;
			clock-names = "ssi-all\0ssi.9\0ssi.8\0ssi.7\0ssi.6\0ssi.5\0ssi.4\0ssi.3\0ssi.2\0ssi.1\0ssi.0\0src.9\0src.8\0src.7\0src.6\0src.5\0src.4\0src.3\0src.2\0src.1\0src.0\0mix.1\0mix.0\0ctu.1\0ctu.0\0dvc.0\0dvc.1\0clk_a\0clk_b\0clk_c\0clk_i";
			power-domains = <0x09 0x20>;
			resets = <0x0c 0x3ed 0x0c 0x3ee 0x0c 0x3ef 0x0c 0x3f0 0x0c 0x3f1 0x0c 0x3f2 0x0c 0x3f3 0x0c 0x3f4 0x0c 0x3f5 0x0c 0x3f6 0x0c 0x3f7>;
			reset-names = "ssi-all\0ssi.9\0ssi.8\0ssi.7\0ssi.6\0ssi.5\0ssi.4\0ssi.3\0ssi.2\0ssi.1\0ssi.0";
			status = "okay";
			pinctrl-0 = <0x79 0x7a 0x7b>;
			pinctrl-names = "default";
			#sound-dai-cells = <0x01>;
			#clock-cells = <0x01>;
			clock-frequency = <0xbb8000 0xac4400>;
			phandle = <0x22>;

			rcar_sound,dvc {

				dvc-0 {
					dmas = <0x7c 0xbc>;
					dma-names = "tx";
					phandle = <0x81>;
				};

				dvc-1 {
					dmas = <0x7c 0xbe>;
					dma-names = "tx";
					phandle = <0x84>;
				};
			};

			rcar_sound,mix {

				mix-0 {
				};

				mix-1 {
				};
			};

			rcar_sound,ctu {

				ctu-0 {
				};

				ctu-1 {
				};

				ctu-2 {
				};

				ctu-3 {
				};

				ctu-4 {
				};

				ctu-5 {
				};

				ctu-6 {
				};

				ctu-7 {
				};
			};

			rcar_sound,src {

				src-0 {
					interrupts = <0x00 0x160 0x04>;
					dmas = <0x7d 0x85 0x7c 0x9a>;
					dma-names = "rx\0tx";
					phandle = <0x80>;
				};

				src-1 {
					interrupts = <0x00 0x161 0x04>;
					dmas = <0x7d 0x87 0x7c 0x9c>;
					dma-names = "rx\0tx";
					phandle = <0x83>;
				};

				src-2 {
					interrupts = <0x00 0x162 0x04>;
					dmas = <0x7d 0x89 0x7c 0x9e>;
					dma-names = "rx\0tx";
				};

				src-3 {
					interrupts = <0x00 0x163 0x04>;
					dmas = <0x7d 0x8b 0x7c 0xa0>;
					dma-names = "rx\0tx";
				};

				src-4 {
					interrupts = <0x00 0x164 0x04>;
					dmas = <0x7d 0x8d 0x7c 0xb0>;
					dma-names = "rx\0tx";
				};

				src-5 {
					interrupts = <0x00 0x165 0x04>;
					dmas = <0x7d 0x8f 0x7c 0xb2>;
					dma-names = "rx\0tx";
				};

				src-6 {
					interrupts = <0x00 0x166 0x04>;
					dmas = <0x7d 0x91 0x7c 0xb4>;
					dma-names = "rx\0tx";
				};

				src-7 {
					interrupts = <0x00 0x167 0x04>;
					dmas = <0x7d 0x93 0x7c 0xb6>;
					dma-names = "rx\0tx";
				};

				src-8 {
					interrupts = <0x00 0x168 0x04>;
					dmas = <0x7d 0x95 0x7c 0xb8>;
					dma-names = "rx\0tx";
				};

				src-9 {
					interrupts = <0x00 0x169 0x04>;
					dmas = <0x7d 0x97 0x7c 0xba>;
					dma-names = "rx\0tx";
				};
			};

			rcar_sound,ssiu {

				ssiu-0 {
					dmas = <0x7d 0x15 0x7c 0x16>;
					dma-names = "rx\0tx";
				};

				ssiu-1 {
					dmas = <0x7d 0x35 0x7c 0x36>;
					dma-names = "rx\0tx";
				};

				ssiu-2 {
					dmas = <0x7d 0x37 0x7c 0x38>;
					dma-names = "rx\0tx";
				};

				ssiu-3 {
					dmas = <0x7d 0x47 0x7c 0x48>;
					dma-names = "rx\0tx";
				};

				ssiu-4 {
					dmas = <0x7d 0x3f 0x7c 0x40>;
					dma-names = "rx\0tx";
				};

				ssiu-5 {
					dmas = <0x7d 0x43 0x7c 0x44>;
					dma-names = "rx\0tx";
				};

				ssiu-6 {
					dmas = <0x7d 0x4f 0x7c 0x50>;
					dma-names = "rx\0tx";
				};

				ssiu-7 {
					dmas = <0x7d 0x53 0x7c 0x54>;
					dma-names = "rx\0tx";
				};

				ssiu-8 {
					dmas = <0x7d 0x49 0x7c 0x4a>;
					dma-names = "rx\0tx";
				};

				ssiu-9 {
					dmas = <0x7d 0x4b 0x7c 0x4c>;
					dma-names = "rx\0tx";
				};

				ssiu-10 {
					dmas = <0x7d 0x57 0x7c 0x58>;
					dma-names = "rx\0tx";
				};

				ssiu-11 {
					dmas = <0x7d 0x59 0x7c 0x5a>;
					dma-names = "rx\0tx";
				};

				ssiu-12 {
					dmas = <0x7d 0x5f 0x7c 0x60>;
					dma-names = "rx\0tx";
				};

				ssiu-13 {
					dmas = <0x7d 0xc3 0x7c 0xc4>;
					dma-names = "rx\0tx";
				};

				ssiu-14 {
					dmas = <0x7d 0xc7 0x7c 0xc8>;
					dma-names = "rx\0tx";
				};

				ssiu-15 {
					dmas = <0x7d 0xcb 0x7c 0xcc>;
					dma-names = "rx\0tx";
				};

				ssiu-16 {
					dmas = <0x7d 0x63 0x7c 0x64>;
					dma-names = "rx\0tx";
				};

				ssiu-17 {
					dmas = <0x7d 0x67 0x7c 0x68>;
					dma-names = "rx\0tx";
				};

				ssiu-18 {
					dmas = <0x7d 0x6b 0x7c 0x6c>;
					dma-names = "rx\0tx";
				};

				ssiu-19 {
					dmas = <0x7d 0x6d 0x7c 0x6e>;
					dma-names = "rx\0tx";
				};

				ssiu-20 {
					dmas = <0x7d 0xcf 0x7c 0xce>;
					dma-names = "rx\0tx";
				};

				ssiu-21 {
					dmas = <0x7d 0xeb 0x7c 0xec>;
					dma-names = "rx\0tx";
				};

				ssiu-22 {
					dmas = <0x7d 0xed 0x7c 0xee>;
					dma-names = "rx\0tx";
				};

				ssiu-23 {
					dmas = <0x7d 0xef 0x7c 0xf0>;
					dma-names = "rx\0tx";
				};

				ssiu-24 {
					dmas = <0x7d 0x6f 0x7c 0x70>;
					dma-names = "rx\0tx";
				};

				ssiu-25 {
					dmas = <0x7d 0x21 0x7c 0x22>;
					dma-names = "rx\0tx";
				};

				ssiu-26 {
					dmas = <0x7d 0x23 0x7c 0x24>;
					dma-names = "rx\0tx";
				};

				ssiu-27 {
					dmas = <0x7d 0x25 0x7c 0x26>;
					dma-names = "rx\0tx";
				};

				ssiu-28 {
					dmas = <0x7d 0x27 0x7c 0x28>;
					dma-names = "rx\0tx";
				};

				ssiu-29 {
					dmas = <0x7d 0x29 0x7c 0x2a>;
					dma-names = "rx\0tx";
				};

				ssiu-30 {
					dmas = <0x7d 0x2b 0x7c 0x2c>;
					dma-names = "rx\0tx";
				};

				ssiu-31 {
					dmas = <0x7d 0x2d 0x7c 0x2e>;
					dma-names = "rx\0tx";
				};

				ssiu-32 {
					dmas = <0x7d 0x71 0x7c 0x72>;
					dma-names = "rx\0tx";
				};

				ssiu-33 {
					dmas = <0x7d 0x17 0x7c 0x18>;
					dma-names = "rx\0tx";
				};

				ssiu-34 {
					dmas = <0x7d 0x19 0x7c 0x1a>;
					dma-names = "rx\0tx";
				};

				ssiu-35 {
					dmas = <0x7d 0x1b 0x7c 0x1c>;
					dma-names = "rx\0tx";
				};

				ssiu-36 {
					dmas = <0x7d 0x1d 0x7c 0x1e>;
					dma-names = "rx\0tx";
				};

				ssiu-37 {
					dmas = <0x7d 0x1f 0x7c 0x20>;
					dma-names = "rx\0tx";
				};

				ssiu-38 {
					dmas = <0x7d 0x31 0x7c 0x32>;
					dma-names = "rx\0tx";
				};

				ssiu-39 {
					dmas = <0x7d 0x33 0x7c 0x34>;
					dma-names = "rx\0tx";
				};

				ssiu-40 {
					dmas = <0x7d 0x73 0x7c 0x74>;
					dma-names = "rx\0tx";
				};

				ssiu-41 {
					dmas = <0x7d 0x75 0x7c 0x76>;
					dma-names = "rx\0tx";
				};

				ssiu-42 {
					dmas = <0x7d 0x79 0x7c 0x7a>;
					dma-names = "rx\0tx";
				};

				ssiu-43 {
					dmas = <0x7d 0x7b 0x7c 0x7c>;
					dma-names = "rx\0tx";
				};

				ssiu-44 {
					dmas = <0x7d 0x7d 0x7c 0x7e>;
					dma-names = "rx\0tx";
				};

				ssiu-45 {
					dmas = <0x7d 0x7f 0x7c 0x80>;
					dma-names = "rx\0tx";
				};

				ssiu-46 {
					dmas = <0x7d 0x81 0x7c 0x82>;
					dma-names = "rx\0tx";
				};

				ssiu-47 {
					dmas = <0x7d 0x83 0x7c 0x84>;
					dma-names = "rx\0tx";
				};

				ssiu-48 {
					dmas = <0x7d 0xa3 0x7c 0xa4>;
					dma-names = "rx\0tx";
				};

				ssiu-49 {
					dmas = <0x7d 0xa5 0x7c 0xa6>;
					dma-names = "rx\0tx";
				};

				ssiu-50 {
					dmas = <0x7d 0xa7 0x7c 0xa8>;
					dma-names = "rx\0tx";
				};

				ssiu-51 {
					dmas = <0x7d 0xa9 0x7c 0xaa>;
					dma-names = "rx\0tx";
				};
			};

			rcar_sound,ssi {

				ssi-0 {
					interrupts = <0x00 0x172 0x04>;
					dmas = <0x7d 0x01 0x7c 0x02>;
					dma-names = "rx\0tx";
					phandle = <0x7f>;
				};

				ssi-1 {
					interrupts = <0x00 0x173 0x04>;
					dmas = <0x7d 0x03 0x7c 0x04>;
					dma-names = "rx\0tx";
					shared-pin;
					phandle = <0x82>;
				};

				ssi-2 {
					interrupts = <0x00 0x174 0x04>;
					dmas = <0x7d 0x05 0x7c 0x06>;
					dma-names = "rx\0tx";
					phandle = <0x87>;
				};

				ssi-3 {
					interrupts = <0x00 0x175 0x04>;
					dmas = <0x7d 0x07 0x7c 0x08>;
					dma-names = "rx\0tx";
					phandle = <0x89>;
				};

				ssi-4 {
					interrupts = <0x00 0x176 0x04>;
					dmas = <0x7d 0x09 0x7c 0x0a>;
					dma-names = "rx\0tx";
					shared-pin;
					phandle = <0x8a>;
				};

				ssi-5 {
					interrupts = <0x00 0x177 0x04>;
					dmas = <0x7d 0x0b 0x7c 0x0c>;
					dma-names = "rx\0tx";
				};

				ssi-6 {
					interrupts = <0x00 0x178 0x04>;
					dmas = <0x7d 0x0d 0x7c 0x0e>;
					dma-names = "rx\0tx";
					phandle = <0x8c>;
				};

				ssi-7 {
					interrupts = <0x00 0x179 0x04>;
					dmas = <0x7d 0x0f 0x7c 0x10>;
					dma-names = "rx\0tx";
					phandle = <0x8e>;
				};

				ssi-8 {
					interrupts = <0x00 0x17a 0x04>;
					dmas = <0x7d 0x11 0x7c 0x12>;
					dma-names = "rx\0tx";
					shared-pin;
					phandle = <0x8f>;
				};

				ssi-9 {
					interrupts = <0x00 0x17b 0x04>;
					dmas = <0x7d 0x13 0x7c 0x14>;
					dma-names = "rx\0tx";
				};
			};

			ports {
				#address-cells = <0x01>;
				#size-cells = <0x00>;

				port@0 {
					reg = <0x00>;
					phandle = <0xdf>;

					endpoint {
						remote-endpoint = <0x7e>;
						dai-format = "left_j";
						bitclock-master = <0x23>;
						frame-master = <0x23>;
						playback = <0x7f 0x80 0x81>;
						capture = <0x82 0x83 0x84>;
						phandle = <0x23>;
					};
				};

				port@1 {
					reg = <0x01>;
					phandle = <0xe0>;

					endpoint {
						remote-endpoint = <0x85>;
						dai-format = "i2s";
						bitclock-master = <0x86>;
						frame-master = <0x86>;
						playback = <0x87>;
						phandle = <0x86>;
					};
				};

				port@2 {
					reg = <0x02>;
					phandle = <0xe1>;

					endpoint {
						remote-endpoint = <0x88>;
						dai-format = "i2s";
						bitclock-master = <0x2e>;
						frame-master = <0x2e>;
						dai-tdm-slot-num = <0x08>;
						dai-tdm-slot-width = <0x20>;
						playback = <0x89>;
						capture = <0x8a>;
						phandle = <0x2e>;
					};
				};

				port@3 {
					reg = <0x03>;
					phandle = <0xe2>;

					endpoint {
						remote-endpoint = <0x8b>;
						dai-format = "i2s";
						bitclock-master = <0x8b>;
						frame-master = <0x8b>;
						capture = <0x8c>;
						phandle = <0xe6>;
					};
				};

				port@4 {
					reg = <0x04>;
					phandle = <0xe3>;

					endpoint {
						remote-endpoint = <0x8d>;
						simple-audio-card,format = "i2s";
						bitclock-master = <0x8d>;
						frame-master = <0x8d>;
						playback = <0x8e>;
						capture = <0x8f>;
						phandle = <0xe7>;
					};
				};
			};
		};

		dma-controller@ec700000 {
			compatible = "renesas,dmac-r8a7795\0renesas,rcar-dmac";
			reg = <0x00 0xec700000 0x00 0x10000>;
			interrupts = <0x00 0x15e 0x04 0x00 0x140 0x04 0x00 0x141 0x04 0x00 0x142 0x04 0x00 0x143 0x04 0x00 0x144 0x04 0x00 0x145 0x04 0x00 0x146 0x04 0x00 0x147 0x04 0x00 0x148 0x04 0x00 0x149 0x04 0x00 0x14a 0x04 0x00 0x14b 0x04 0x00 0x14c 0x04 0x00 0x14d 0x04 0x00 0x14e 0x04 0x00 0x14f 0x04>;
			interrupt-names = "error\0ch0\0ch1\0ch2\0ch3\0ch4\0ch5\0ch6\0ch7\0ch8\0ch9\0ch10\0ch11\0ch12\0ch13\0ch14\0ch15";
			clocks = <0x0c 0x01 0x1f6>;
			clock-names = "fck";
			power-domains = <0x09 0x20>;
			resets = <0x0c 0x1f6>;
			#dma-cells = <0x01>;
			dma-channels = <0x10>;
			phandle = <0x7d>;
		};

		dma-controller@ec720000 {
			compatible = "renesas,dmac-r8a7795\0renesas,rcar-dmac";
			reg = <0x00 0xec720000 0x00 0x10000>;
			interrupts = <0x00 0x15f 0x04 0x00 0x150 0x04 0x00 0x151 0x04 0x00 0x152 0x04 0x00 0x153 0x04 0x00 0x154 0x04 0x00 0x155 0x04 0x00 0x156 0x04 0x00 0x157 0x04 0x00 0x158 0x04 0x00 0x159 0x04 0x00 0x15a 0x04 0x00 0x15b 0x04 0x00 0x15c 0x04 0x00 0x15d 0x04 0x00 0x17e 0x04 0x00 0x17f 0x04>;
			interrupt-names = "error\0ch0\0ch1\0ch2\0ch3\0ch4\0ch5\0ch6\0ch7\0ch8\0ch9\0ch10\0ch11\0ch12\0ch13\0ch14\0ch15";
			clocks = <0x0c 0x01 0x1f5>;
			clock-names = "fck";
			power-domains = <0x09 0x20>;
			resets = <0x0c 0x1f5>;
			#dma-cells = <0x01>;
			dma-channels = <0x10>;
			phandle = <0x7c>;
		};

		adsp@ec800000 {
			compatible = "renesas,r8a7795-adsp\0renesas,rcar-gen3-adsp";
			reg = <0x00 0xec800000 0x00 0x80fc 0x00 0xece60000 0x00 0x10000 0x00 0xece78000 0x00 0x8000 0x00 0xece80000 0x00 0x10000 0x00 0xece90000 0x00 0x10000>;
			interrupts = <0x00 0xed 0x04>;
			clocks = <0x0c 0x01 0x1fa 0x0c 0x01 0x3ed 0x0c 0x01 0x3ee 0x0c 0x01 0x3ef 0x0c 0x01 0x3f0 0x0c 0x01 0x3f1 0x0c 0x01 0x3f2 0x0c 0x01 0x3f3 0x0c 0x01 0x3f4 0x0c 0x01 0x3f5 0x0c 0x01 0x3f6 0x0c 0x01 0x3f7 0x0c 0x01 0x3fe 0x0c 0x01 0x3ff 0x0c 0x01 0x400 0x0c 0x01 0x401 0x0c 0x01 0x402 0x0c 0x01 0x403 0x0c 0x01 0x404 0x0c 0x01 0x405 0x0c 0x01 0x406 0x0c 0x01 0x407 0x0c 0x01 0x3fc 0x0c 0x01 0x3fd 0x0c 0x01 0x3fc 0x0c 0x01 0x3fd 0x0c 0x01 0x3fb 0x0c 0x01 0x3fa 0x0c 0x01 0x1f5 0x0c 0x01 0x1f6 0x0c 0x01 0x39a>;
			clock-names = "adsp\0ssi-all\0ssi.9\0ssi.8\0ssi.7\0ssi.6\0ssi.5\0ssi.4\0ssi.3\0ssi.2\0ssi.1\0ssi.0\0src.9\0src.8\0src.7\0src.6\0src.5\0src.4\0src.3\0src.2\0src.1\0src.0\0mix.1\0mix.0\0ctu.1\0ctu.0\0dvc.0\0dvc.1\0audmac.1\0audmac.0\0adg";
			power-domains = <0x09 0x20>;
			resets = <0x0c 0x1fa 0x0c 0x3ed 0x0c 0x3ee 0x0c 0x3ef 0x0c 0x3f0 0x0c 0x3f1 0x0c 0x3f2 0x0c 0x3f3 0x0c 0x3f4 0x0c 0x3f5 0x0c 0x3f6 0x0c 0x3f7 0x0c 0x1f5 0x0c 0x1f6 0x0c 0x39a>;
			reset-names = "adsp\0ssi-all\0ssi.9\0ssi.8\0ssi.7\0ssi.6\0ssi.5\0ssi.4\0ssi.3\0ssi.2\0ssi.1\0ssi.0\0audmac.1\0audmac.0\0adg";
			status = "disabled";
		};

		usb@ee000000 {
			compatible = "renesas,xhci-r8a7795\0renesas,rcar-gen3-xhci";
			reg = <0x00 0xee000000 0x00 0xc00>;
			interrupts = <0x00 0x66 0x04>;
			clocks = <0x0c 0x01 0x148>;
			power-domains = <0x09 0x20>;
			resets = <0x0c 0x148>;
			status = "okay";
		};

		usb@ee020000 {
			compatible = "renesas,r8a7795-usb3-peri\0renesas,rcar-gen3-usb3-peri";
			reg = <0x00 0xee020000 0x00 0x400>;
			interrupts = <0x00 0x68 0x04>;
			clocks = <0x0c 0x01 0x148>;
			power-domains = <0x09 0x20>;
			resets = <0x0c 0x148>;
			status = "disabled";
		};

		usb@ee080000 {
			compatible = "generic-ohci";
			reg = <0x00 0xee080000 0x00 0x100>;
			interrupts = <0x00 0x6c 0x04>;
			clocks = <0x0c 0x01 0x2bf 0x0c 0x01 0x2c0>;
			phys = <0x4c 0x01>;
			phy-names = "usb";
			power-domains = <0x09 0x20>;
			resets = <0x0c 0x2bf 0x0c 0x2c0>;
			status = "okay";
			dr_mode = "otg";
			phandle = <0x92>;
		};

		usb@ee0a0000 {
			compatible = "generic-ohci";
			reg = <0x00 0xee0a0000 0x00 0x100>;
			interrupts = <0x00 0x70 0x04>;
			clocks = <0x0c 0x01 0x2be>;
			phys = <0x90 0x01>;
			phy-names = "usb";
			power-domains = <0x09 0x20>;
			resets = <0x0c 0x2be>;
			status = "okay";
			phandle = <0x93>;
		};

		usb@ee0c0000 {
			compatible = "generic-ohci";
			reg = <0x00 0xee0c0000 0x00 0x100>;
			interrupts = <0x00 0x71 0x04>;
			clocks = <0x0c 0x01 0x2bd>;
			phys = <0x91 0x01>;
			phy-names = "usb";
			power-domains = <0x09 0x20>;
			resets = <0x0c 0x2bd>;
			status = "disabled";
			phandle = <0x94>;
		};

		usb@ee0e0000 {
			compatible = "generic-ohci";
			reg = <0x00 0xee0e0000 0x00 0x100>;
			interrupts = <0x00 0x24 0x04>;
			clocks = <0x0c 0x01 0x2bc 0x0c 0x01 0x2c1>;
			phys = <0x4f 0x01>;
			phy-names = "usb";
			power-domains = <0x09 0x20>;
			resets = <0x0c 0x2bc 0x0c 0x2c1>;
			status = "disabled";
			phandle = <0x95>;
		};

		usb@ee080100 {
			compatible = "generic-ehci";
			reg = <0x00 0xee080100 0x00 0x100>;
			interrupts = <0x00 0x6c 0x04>;
			clocks = <0x0c 0x01 0x2bf 0x0c 0x01 0x2c0>;
			phys = <0x4c 0x02>;
			phy-names = "usb";
			companion = <0x92>;
			power-domains = <0x09 0x20>;
			resets = <0x0c 0x2bf 0x0c 0x2c0>;
			status = "okay";
			dr_mode = "otg";
		};

		usb@ee0a0100 {
			compatible = "generic-ehci";
			reg = <0x00 0xee0a0100 0x00 0x100>;
			interrupts = <0x00 0x70 0x04>;
			clocks = <0x0c 0x01 0x2be>;
			phys = <0x90 0x02>;
			phy-names = "usb";
			companion = <0x93>;
			power-domains = <0x09 0x20>;
			resets = <0x0c 0x2be>;
			status = "okay";
		};

		usb@ee0c0100 {
			compatible = "generic-ehci";
			reg = <0x00 0xee0c0100 0x00 0x100>;
			interrupts = <0x00 0x71 0x04>;
			clocks = <0x0c 0x01 0x2bd>;
			phys = <0x91 0x02>;
			phy-names = "usb";
			companion = <0x94>;
			power-domains = <0x09 0x20>;
			resets = <0x0c 0x2bd>;
			status = "disabled";
		};

		usb@ee0e0100 {
			compatible = "generic-ehci";
			reg = <0x00 0xee0e0100 0x00 0x100>;
			interrupts = <0x00 0x24 0x04>;
			clocks = <0x0c 0x01 0x2bc 0x0c 0x01 0x2c1>;
			phys = <0x4f 0x02>;
			phy-names = "usb";
			companion = <0x95>;
			power-domains = <0x09 0x20>;
			resets = <0x0c 0x2bc 0x0c 0x2c1>;
			status = "disabled";
		};

		usb-phy@ee080200 {
			compatible = "renesas,usb2-phy-r8a7795\0renesas,rcar-gen3-usb2-phy";
			reg = <0x00 0xee080200 0x00 0x700>;
			interrupts = <0x00 0x6c 0x04>;
			clocks = <0x0c 0x01 0x2bf 0x0c 0x01 0x2c0>;
			power-domains = <0x09 0x20>;
			resets = <0x0c 0x2bf 0x0c 0x2c0>;
			#phy-cells = <0x01>;
			status = "okay";
			pinctrl-0 = <0x96>;
			pinctrl-names = "default";
			phandle = <0x4c>;
		};

		usb-phy@ee0a0200 {
			compatible = "renesas,usb2-phy-r8a7795\0renesas,rcar-gen3-usb2-phy";
			reg = <0x00 0xee0a0200 0x00 0x700>;
			clocks = <0x0c 0x01 0x2be>;
			power-domains = <0x09 0x20>;
			resets = <0x0c 0x2be>;
			#phy-cells = <0x01>;
			status = "okay";
			pinctrl-0 = <0x97>;
			pinctrl-names = "default";
			phandle = <0x90>;
		};

		usb-phy@ee0c0200 {
			compatible = "renesas,usb2-phy-r8a7795\0renesas,rcar-gen3-usb2-phy";
			reg = <0x00 0xee0c0200 0x00 0x700>;
			clocks = <0x0c 0x01 0x2bd>;
			power-domains = <0x09 0x20>;
			resets = <0x0c 0x2bd>;
			#phy-cells = <0x01>;
			status = "disabled";
			phandle = <0x91>;
		};

		usb-phy@ee0e0200 {
			compatible = "renesas,usb2-phy-r8a7795\0renesas,rcar-gen3-usb2-phy";
			reg = <0x00 0xee0e0200 0x00 0x700>;
			interrupts = <0x00 0x24 0x04>;
			clocks = <0x0c 0x01 0x2bc 0x0c 0x01 0x2c1>;
			power-domains = <0x09 0x20>;
			resets = <0x0c 0x2bc 0x0c 0x2c1>;
			#phy-cells = <0x01>;
			status = "disabled";
			phandle = <0x4f>;
		};

		mmc@ee100000 {
			compatible = "renesas,sdhi-r8a7795\0renesas,rcar-gen3-sdhi";
			reg = <0x00 0xee100000 0x00 0x2000>;
			interrupts = <0x00 0xa5 0x04>;
			clocks = <0x0c 0x01 0x13a>;
			max-frequency = <0xbebc200>;
			power-domains = <0x09 0x20>;
			resets = <0x0c 0x13a>;
			status = "okay";
			pinctrl-0 = <0x98>;
			pinctrl-1 = <0x99>;
			pinctrl-names = "default\0state_uhs";
			vmmc-supply = <0x9a>;
			vqmmc-supply = <0x9b>;
			cd-gpios = <0x32 0x0c 0x01>;
			bus-width = <0x04>;
			sd-uhs-sdr50;
			sd-uhs-sdr104;
		};

		mmc@ee120000 {
			compatible = "renesas,sdhi-r8a7795\0renesas,rcar-gen3-sdhi";
			reg = <0x00 0xee120000 0x00 0x2000>;
			interrupts = <0x00 0xa6 0x04>;
			clocks = <0x0c 0x01 0x139>;
			max-frequency = <0xbebc200>;
			power-domains = <0x09 0x20>;
			resets = <0x0c 0x139>;
			status = "disabled";
		};

		mmc@ee140000 {
			compatible = "renesas,sdhi-r8a7795\0renesas,rcar-gen3-sdhi";
			reg = <0x00 0xee140000 0x00 0x2000>;
			interrupts = <0x00 0xa7 0x04>;
			clocks = <0x0c 0x01 0x138>;
			max-frequency = <0xbebc200>;
			power-domains = <0x09 0x20>;
			resets = <0x0c 0x138>;
			status = "okay";
			pinctrl-0 = <0x9c>;
			pinctrl-1 = <0x9c>;
			pinctrl-names = "default\0state_uhs";
			iommus = <0x9d 0x22>;
			vmmc-supply = <0x9e>;
			vqmmc-supply = <0x9f>;
			bus-width = <0x08>;
			mmc-hs200-1_8v;
			mmc-hs400-1_8v;
			no-sd;
			no-sdio;
			non-removable;
			full-pwr-cycle-in-suspend;
		};

		mmc@ee160000 {
			compatible = "renesas,sdhi-r8a7795\0renesas,rcar-gen3-sdhi";
			reg = <0x00 0xee160000 0x00 0x2000>;
			interrupts = <0x00 0xa8 0x04>;
			clocks = <0x0c 0x01 0x137>;
			max-frequency = <0x2faf080>;
			power-domains = <0x09 0x20>;
			resets = <0x0c 0x137>;
			status = "okay";
			pinctrl-0 = <0xa0>;
			pinctrl-names = "default";
			vmmc-supply = <0xa1>;
			vqmmc-supply = <0xa1>;
			bus-width = <0x04>;
			no-1-8-v;
			non-removable;
			cap-power-off-card;
			keep-power-in-suspend;
			#address-cells = <0x01>;
			#size-cells = <0x00>;

			wlcore@2 {
				compatible = "ti,wl1837";
				reg = <0x02>;
				interrupt-parent = <0xa2>;
				interrupts = <0x19 0x02>;
			};
		};

		sata@ee300000 {
			compatible = "renesas,sata-r8a7795\0renesas,rcar-gen3-sata";
			reg = <0x00 0xee300000 0x00 0x200000>;
			interrupts = <0x00 0x69 0x04>;
			clocks = <0x0c 0x01 0x32f>;
			power-domains = <0x09 0x20>;
			resets = <0x0c 0x32f>;
			status = "disabled";
		};

		interrupt-controller@f1010000 {
			compatible = "arm,gic-400";
			#interrupt-cells = <0x03>;
			#address-cells = <0x00>;
			interrupt-controller;
			reg = <0x00 0xf1010000 0x00 0x1000 0x00 0xf1020000 0x00 0x20000 0x00 0xf1040000 0x00 0x20000 0x00 0xf1060000 0x00 0x20000>;
			interrupts = <0x01 0x09 0xff04>;
			power-domains = <0x09 0x20>;
			phandle = <0x19>;
		};

		gsx@fd000000 {
			compatible = "renesas,gsx";
			reg = <0x00 0xfd000000 0x00 0x40000>;
			interrupts = <0x00 0x77 0x04>;
			clocks = <0x0c 0x01 0x70>;
			operating-points-v2 = <0xa3 0xa4 0xa5 0xa6 0xa7 0xa8 0xa9 0xaa>;
			power-domains = <0x09 0x16>;
			resets = <0x0c 0x70>;
			phandle = <0x1c>;
		};

		pcie@fe000000 {
			compatible = "renesas,pcie-r8a7795\0renesas,pcie-rcar-gen3";
			reg = <0x00 0xfe000000 0x00 0x80000>;
			#address-cells = <0x03>;
			#size-cells = <0x02>;
			bus-range = <0x00 0xff>;
			device_type = "pci";
			ranges = <0x1000000 0x00 0x00 0x00 0xfe100000 0x00 0x100000 0x2000000 0x00 0xfe200000 0x00 0xfe200000 0x00 0x200000 0x2000000 0x00 0x30000000 0x00 0x30000000 0x00 0x8000000 0x42000000 0x00 0x38000000 0x00 0x38000000 0x00 0x8000000>;
			dma-ranges = <0x42000000 0x00 0x40000000 0x00 0x40000000 0x00 0x40000000>;
			interrupts = <0x00 0x74 0x04 0x00 0x75 0x04 0x00 0x76 0x04>;
			#interrupt-cells = <0x01>;
			interrupt-map-mask = <0x00 0x00 0x00 0x00>;
			interrupt-map = <0x00 0x00 0x00 0x00 0x19 0x00 0x74 0x04>;
			clocks = <0x0c 0x01 0x13f 0xab>;
			clock-names = "pcie\0pcie_bus";
			power-domains = <0x09 0x20>;
			resets = <0x0c 0x13f>;
			status = "okay";
		};

		pcie@ee800000 {
			compatible = "renesas,pcie-r8a7795\0renesas,pcie-rcar-gen3";
			reg = <0x00 0xee800000 0x00 0x80000>;
			#address-cells = <0x03>;
			#size-cells = <0x02>;
			bus-range = <0x00 0xff>;
			device_type = "pci";
			ranges = <0x1000000 0x00 0x00 0x00 0xee900000 0x00 0x100000 0x2000000 0x00 0xeea00000 0x00 0xeea00000 0x00 0x200000 0x2000000 0x00 0xc0000000 0x00 0xc0000000 0x00 0x8000000 0x42000000 0x00 0xc8000000 0x00 0xc8000000 0x00 0x8000000>;
			dma-ranges = <0x42000000 0x00 0x40000000 0x00 0x40000000 0x00 0x40000000>;
			interrupts = <0x00 0x94 0x04 0x00 0x95 0x04 0x00 0x96 0x04>;
			#interrupt-cells = <0x01>;
			interrupt-map-mask = <0x00 0x00 0x00 0x00>;
			interrupt-map = <0x00 0x00 0x00 0x00 0x19 0x00 0x94 0x04>;
			clocks = <0x0c 0x01 0x13e 0xab>;
			clock-names = "pcie\0pcie_bus";
			power-domains = <0x09 0x20>;
			resets = <0x0c 0x13e>;
			status = "okay";
			pcie3v3-supply = <0xac>;
			pcie1v8-supply = <0xad>;
		};

		pcie-ep@fe000000 {
			compatible = "renesas,r8a7795-pcie-ep\0renesas,rcar-gen3-pcie-ep";
			reg = <0x00 0xfe000000 0x00 0x80000 0x00 0xfe100000 0x00 0x100000 0x00 0xfe200000 0x00 0x200000 0x00 0x30000000 0x00 0x8000000 0x00 0x38000000 0x00 0x8000000>;
			reg-names = "apb-base\0memory0\0memory1\0memory2\0memory3";
			interrupts = <0x00 0x74 0x04 0x00 0x75 0x04 0x00 0x76 0x04>;
			clocks = <0x0c 0x01 0x13f>;
			clock-names = "pcie";
			resets = <0x0c 0x13f>;
			power-domains = <0x09 0x20>;
			status = "disabled";
		};

		pcie-ep@ee800000 {
			compatible = "renesas,r8a7795-pcie-ep\0renesas,rcar-gen3-pcie-ep";
			reg = <0x00 0xee800000 0x00 0x80000 0x00 0xee900000 0x00 0x100000 0x00 0xeea00000 0x00 0x200000 0x00 0xc0000000 0x00 0x8000000 0x00 0xc8000000 0x00 0x8000000>;
			reg-names = "apb-base\0memory0\0memory1\0memory2\0memory3";
			interrupts = <0x00 0x94 0x04 0x00 0x95 0x04 0x00 0x96 0x04>;
			clocks = <0x0c 0x01 0x13e>;
			clock-names = "pcie";
			resets = <0x0c 0x13e>;
			power-domains = <0x09 0x20>;
			status = "disabled";
		};

		imr-lx4@fe860000 {
			compatible = "renesas,r8a7795-imr-lx4\0renesas,imr-lx4";
			reg = <0x00 0xfe860000 0x00 0x2000>;
			interrupts = <0x00 0xc0 0x04>;
			clocks = <0x0c 0x01 0x337>;
			power-domains = <0x09 0x0e>;
			resets = <0x0c 0x337>;
		};

		imr-lx4@fe870000 {
			compatible = "renesas,r8a7795-imr-lx4\0renesas,imr-lx4";
			reg = <0x00 0xfe870000 0x00 0x2000>;
			interrupts = <0x00 0xc1 0x04>;
			clocks = <0x0c 0x01 0x336>;
			power-domains = <0x09 0x0e>;
			resets = <0x0c 0x336>;
		};

		imr-lx4@fe880000 {
			compatible = "renesas,r8a7795-imr-lx4\0renesas,imr-lx4";
			reg = <0x00 0xfe880000 0x00 0x2000>;
			interrupts = <0x00 0xc2 0x04>;
			clocks = <0x0c 0x01 0x335>;
			power-domains = <0x09 0x0e>;
			resets = <0x0c 0x335>;
		};

		imr-lx4@fe890000 {
			compatible = "renesas,r8a7795-imr-lx4\0renesas,imr-lx4";
			reg = <0x00 0xfe890000 0x00 0x2000>;
			interrupts = <0x00 0xc3 0x04>;
			clocks = <0x0c 0x01 0x334>;
			power-domains = <0x09 0x0e>;
			resets = <0x0c 0x334>;
		};

		vcp4@fe90f000 {
			compatible = "renesas,vcp4-fcpcs";
			reg = <0x00 0xfe90f000 0x00 0x200>;
			clocks = <0x0c 0x01 0x26b>;
			power-domains = <0x09 0x0e>;
			resets = <0x0c 0x26b>;
			renesas,#ch = <0x00>;
		};

		vcp4@fe8d0000 {
			compatible = "renesas,vcp4-ivdp1c";
			reg = <0x00 0xfe8d0000 0x00 0x200 0x00 0xfe8d0200 0x00 0x200>;
			interrupts = <0x00 0x17c 0x04 0x00 0x17d 0x04 0x00 0xdf 0x04>;
			clocks = <0x0c 0x01 0x82>;
			power-domains = <0x09 0x1a>;
			resets = <0x0c 0x82>;
			renesas,#ch = <0x02>;
			renesas,#fcp_ch = <0x00>;
		};

		vcp4@fe910000 {
			compatible = "renesas,vcp4-vcplf";
			reg = <0x00 0xfe910000 0x00 0x200 0x00 0xfe910200 0x00 0x200>;
			interrupts = <0x00 0x104 0x04 0x00 0x105 0x04>;
			clocks = <0x0c 0x01 0x82>;
			power-domains = <0x09 0x1a>;
			resets = <0x0c 0x82>;
			renesas,#ch = <0x00>;
			renesas,#fcp_ch = <0x00>;
		};

		vcp4@fe900000 {
			compatible = "renesas,vcp4-vdpb";
			reg = <0x00 0xfe900000 0x00 0x200 0x00 0xfe900200 0x00 0x200>;
			interrupts = <0x00 0xf0 0x04 0x00 0xf1 0x04>;
			clocks = <0x0c 0x01 0x83>;
			power-domains = <0x09 0x1a>;
			resets = <0x0c 0x83>;
			renesas,#ch = <0x01>;
			renesas,#fcp_ch = <0x00>;
		};

		fdpm@fe940000 {
			compatible = "renesas,fdpm";
			reg = <0x00 0xfe940000 0x00 0x2400 0x00 0xfe950000 0x00 0x200>;
			interrupts = <0x00 0x106 0x04>;
			clocks = <0x0c 0x01 0x77 0x0c 0x01 0x267>;
			clock-names = "fdp\0fcp";
			power-domains = <0x09 0x09>;
			resets = <0x0c 0x77 0x0c 0x267>;
			reset-names = "fdp\0fcp";
			renesas,#ch = <0x00>;
		};

		fdpm@fe944000 {
			compatible = "renesas,fdpm";
			reg = <0x00 0xfe944000 0x00 0x2400 0x00 0xfe951000 0x00 0x200>;
			interrupts = <0x00 0x107 0x04>;
			clocks = <0x0c 0x01 0x76 0x0c 0x01 0x266>;
			clock-names = "fdp\0fcp";
			power-domains = <0x09 0x09>;
			resets = <0x0c 0x76 0x0c 0x266>;
			reset-names = "fdp\0fcp";
			renesas,#ch = <0x01>;
		};

		fcp@fea27000 {
			compatible = "renesas,fcpv";
			reg = <0x00 0xfea27000 0x00 0x200>;
			clocks = <0x0c 0x01 0x25b>;
			power-domains = <0x09 0x20>;
			resets = <0x0c 0x25b>;
			phandle = <0xae>;
		};

		fcp@fea2f000 {
			compatible = "renesas,fcpv";
			reg = <0x00 0xfea2f000 0x00 0x200>;
			clocks = <0x0c 0x01 0x25a>;
			power-domains = <0x09 0x20>;
			resets = <0x0c 0x25a>;
			phandle = <0xaf>;
		};

		fcp@fea37000 {
			compatible = "renesas,fcpv";
			reg = <0x00 0xfea37000 0x00 0x200>;
			clocks = <0x0c 0x01 0x259>;
			power-domains = <0x09 0x20>;
			resets = <0x0c 0x259>;
			phandle = <0xb0>;
		};

		vsp@fe920000 {
			compatible = "renesas,vspm-vsp2";
			reg = <0x00 0xfe920000 0x00 0x8000>;
			renesas,has-bru;
			renesas,has-lut;
			renesas,has-clu;
			renesas,has-hgo;
			renesas,#rpf = <0x05>;
			renesas,#uds = <0x00>;
			renesas,#wpf = <0x01>;
		};

		vspm@fe920000 {
			compatible = "renesas,vspm";
			reg = <0x00 0xfe920000 0x00 0x8000 0x00 0xfe92f000 0x00 0x200>;
			interrupts = <0x00 0x1d1 0x04>;
			clocks = <0x0c 0x01 0x270 0x0c 0x01 0x25e>;
			clock-names = "vsp\0fcp";
			renesas,#ch = <0x04>;
			renesas,#rpf = <0x1f>;
			renesas,#rpf_clut = <0x06>;
			renesas,#wpf_rot = <0x00>;
			renesas,has-lut;
			renesas,has-clu;
			renesas,has-hgo;
			renesas,has-bru;
			renesas,#read_outstanding = <0x00>;
			renesas,#start_reservation = <0x02>;
			renesas,#burst_access = <0x01>;
			power-domains = <0x09 0x09>;
			resets = <0x0c 0x270 0x0c 0x25e>;
			reset-names = "vsp\0fcp";
			status = "okay";
		};

		vsp@fe960000 {
			compatible = "renesas,vspm-vsp2";
			reg = <0x00 0xfe960000 0x00 0x8000>;
			renesas,has-bru;
			renesas,#rpf = <0x05>;
			renesas,#uds = <0x00>;
			renesas,#wpf = <0x01>;
		};

		vspm@fe960000 {
			compatible = "renesas,vspm";
			reg = <0x00 0xfe960000 0x00 0x8000 0x00 0xfe96f000 0x00 0x200>;
			interrupts = <0x00 0x10a 0x04>;
			clocks = <0x0c 0x01 0x272 0x0c 0x01 0x25f>;
			clock-names = "vsp\0fcp";
			renesas,#ch = <0x03>;
			renesas,#rpf = <0x1f>;
			renesas,#rpf_clut = <0x06>;
			renesas,#wpf_rot = <0x00>;
			renesas,has-bru;
			renesas,#read_outstanding = <0x00>;
			renesas,#start_reservation = <0x02>;
			renesas,#burst_access = <0x00>;
			power-domains = <0x09 0x09>;
			resets = <0x0c 0x272 0x0c 0x25f>;
			reset-names = "vsp\0fcp";
			status = "okay";
		};

		vsp@fea20000 {
			compatible = "renesas,vsp2";
			reg = <0x00 0xfea20000 0x00 0x5000>;
			interrupts = <0x00 0x1d2 0x04>;
			clocks = <0x0c 0x01 0x26f>;
			power-domains = <0x09 0x20>;
			resets = <0x0c 0x26f>;
			renesas,#brs = <0x02>;
			renesas,fcp = <0xae>;
			phandle = <0xcd>;
		};

		vsp@fea28000 {
			compatible = "renesas,vsp2";
			reg = <0x00 0xfea28000 0x00 0x5000>;
			interrupts = <0x00 0x1d3 0x04>;
			clocks = <0x0c 0x01 0x26e>;
			power-domains = <0x09 0x20>;
			resets = <0x0c 0x26e>;
			renesas,fcp = <0xaf>;
			phandle = <0xce>;
		};

		vsp@fea30000 {
			compatible = "renesas,vsp2";
			reg = <0x00 0xfea30000 0x00 0x5000>;
			interrupts = <0x00 0x1d4 0x04>;
			clocks = <0x0c 0x01 0x26d>;
			power-domains = <0x09 0x20>;
			resets = <0x0c 0x26d>;
			renesas,fcp = <0xb0>;
			phandle = <0xcf>;
		};

		vsp@fe9a0000 {
			compatible = "renesas,vspm-vsp2";
			reg = <0x00 0xfe9a0000 0x00 0x8000>;
			renesas,has-lut;
			renesas,has-clu;
			renesas,has-hgo;
			renesas,has-hgt;
			renesas,#rpf = <0x01>;
			renesas,#uds = <0x01>;
			renesas,#wpf = <0x01>;
		};

		vspm@fe9a0000 {
			compatible = "renesas,vspm";
			reg = <0x00 0xfe9a0000 0x00 0x8000 0x00 0xfe9af000 0x00 0x200>;
			interrupts = <0x00 0x1bc 0x04>;
			clocks = <0x0c 0x01 0x277 0x0c 0x01 0x263>;
			clock-names = "vsp\0fcp";
			renesas,#ch = <0x00>;
			renesas,#rpf = <0x01>;
			renesas,#rpf_clut = <0x01>;
			renesas,#wpf_rot = <0x01>;
			renesas,has-sru;
			renesas,has-uds;
			renesas,has-lut;
			renesas,has-clu;
			renesas,has-hst;
			renesas,has-hsi;
			renesas,has-hgo;
			renesas,has-hgt;
			renesas,has-shp;
			renesas,#read_outstanding = <0x02>;
			renesas,#start_reservation = <0x02>;
			power-domains = <0x09 0x09>;
			resets = <0x0c 0x277 0x0c 0x263>;
			reset-names = "vsp\0fcp";
			status = "okay";
		};

		vsp@fe9b0000 {
			compatible = "renesas,vspm-vsp2";
			reg = <0x00 0xfe9b0000 0x00 0x8000>;
			renesas,has-lut;
			renesas,has-clu;
			renesas,has-hgo;
			renesas,has-hgt;
			renesas,#rpf = <0x01>;
			renesas,#uds = <0x01>;
			renesas,#wpf = <0x01>;
		};

		vspm@fe9b0000 {
			compatible = "renesas,vspm";
			reg = <0x00 0xfe9b0000 0x00 0x8000 0x00 0xfe9bf000 0x00 0x200>;
			interrupts = <0x00 0x1bd 0x04>;
			clocks = <0x0c 0x01 0x276 0x0c 0x01 0x262>;
			clock-names = "vsp\0fcp";
			renesas,#ch = <0x01>;
			renesas,#rpf = <0x01>;
			renesas,#rpf_clut = <0x01>;
			renesas,#wpf_rot = <0x01>;
			renesas,has-sru;
			renesas,has-uds;
			renesas,has-lut;
			renesas,has-clu;
			renesas,has-hst;
			renesas,has-hsi;
			renesas,has-hgo;
			renesas,has-hgt;
			renesas,has-shp;
			renesas,#read_outstanding = <0x02>;
			renesas,#start_reservation = <0x02>;
			power-domains = <0x09 0x09>;
			resets = <0x0c 0x276 0x0c 0x262>;
			reset-names = "vsp\0fcp";
			status = "okay";
		};

		cmm@fea40000 {
			compatible = "renesas,r8a7795-cmm\0renesas,rcar-gen3-cmm";
			reg = <0x00 0xfea40000 0x00 0x1000>;
			power-domains = <0x09 0x20>;
			clocks = <0x0c 0x01 0x2c7>;
			resets = <0x0c 0x2c7>;
			phandle = <0xc9>;
		};

		cmm@fea50000 {
			compatible = "renesas,r8a7795-cmm\0renesas,rcar-gen3-cmm";
			reg = <0x00 0xfea50000 0x00 0x1000>;
			power-domains = <0x09 0x20>;
			clocks = <0x0c 0x01 0x2c6>;
			resets = <0x0c 0x2c6>;
			phandle = <0xca>;
		};

		cmm@fea60000 {
			compatible = "renesas,r8a7795-cmm\0renesas,rcar-gen3-cmm";
			reg = <0x00 0xfea60000 0x00 0x1000>;
			power-domains = <0x09 0x20>;
			clocks = <0x0c 0x01 0x2c5>;
			resets = <0x0c 0x2c5>;
			phandle = <0xcb>;
		};

		cmm@fea70000 {
			compatible = "renesas,r8a7795-cmm\0renesas,rcar-gen3-cmm";
			reg = <0x00 0xfea70000 0x00 0x1000>;
			power-domains = <0x09 0x20>;
			clocks = <0x0c 0x01 0x2c4>;
			resets = <0x0c 0x2c4>;
			phandle = <0xcc>;
		};

		csi2@fea80000 {
			compatible = "renesas,r8a7795-csi2";
			reg = <0x00 0xfea80000 0x00 0x10000>;
			interrupts = <0x00 0xb8 0x04>;
			clocks = <0x0c 0x01 0x2ca>;
			power-domains = <0x09 0x20>;
			resets = <0x0c 0x2ca>;
			status = "okay";

			ports {
				#address-cells = <0x01>;
				#size-cells = <0x00>;

				port@0 {
					reg = <0x00>;

					endpoint {
						clock-lanes = <0x00>;
						data-lanes = <0x01 0x02>;
						remote-endpoint = <0xb1>;
						phandle = <0x42>;
					};
				};

				port@1 {
					#address-cells = <0x01>;
					#size-cells = <0x00>;
					reg = <0x01>;

					endpoint@0 {
						reg = <0x00>;
						remote-endpoint = <0xb2>;
						phandle = <0x5d>;
					};

					endpoint@1 {
						reg = <0x01>;
						remote-endpoint = <0xb3>;
						phandle = <0x5f>;
					};

					endpoint@2 {
						reg = <0x02>;
						remote-endpoint = <0xb4>;
						phandle = <0x61>;
					};

					endpoint@3 {
						reg = <0x03>;
						remote-endpoint = <0xb5>;
						phandle = <0x63>;
					};

					endpoint@4 {
						reg = <0x04>;
						remote-endpoint = <0xb6>;
						phandle = <0x65>;
					};

					endpoint@5 {
						reg = <0x05>;
						remote-endpoint = <0xb7>;
						phandle = <0x68>;
					};

					endpoint@6 {
						reg = <0x06>;
						remote-endpoint = <0xb8>;
						phandle = <0x6b>;
					};

					endpoint@7 {
						reg = <0x07>;
						remote-endpoint = <0xb9>;
						phandle = <0x6d>;
					};
				};
			};
		};

		csi2@feaa0000 {
			compatible = "renesas,r8a7795-csi2";
			reg = <0x00 0xfeaa0000 0x00 0x10000>;
			interrupts = <0x00 0xf6 0x04>;
			clocks = <0x0c 0x01 0x2cc>;
			power-domains = <0x09 0x20>;
			resets = <0x0c 0x2cc>;
			status = "okay";

			ports {
				#address-cells = <0x01>;
				#size-cells = <0x00>;

				port@0 {
					reg = <0x00>;

					endpoint {
						clock-lanes = <0x00>;
						data-lanes = <0x01 0x02 0x03 0x04>;
						remote-endpoint = <0xba>;
						phandle = <0x3c>;
					};
				};

				port@1 {
					#address-cells = <0x01>;
					#size-cells = <0x00>;
					reg = <0x01>;

					endpoint@0 {
						reg = <0x00>;
						remote-endpoint = <0xbb>;
						phandle = <0x5e>;
					};

					endpoint@1 {
						reg = <0x01>;
						remote-endpoint = <0xbc>;
						phandle = <0x60>;
					};

					endpoint@2 {
						reg = <0x02>;
						remote-endpoint = <0xbd>;
						phandle = <0x62>;
					};

					endpoint@3 {
						reg = <0x03>;
						remote-endpoint = <0xbe>;
						phandle = <0x64>;
					};
				};
			};
		};

		csi2@feab0000 {
			compatible = "renesas,r8a7795-csi2";
			reg = <0x00 0xfeab0000 0x00 0x10000>;
			interrupts = <0x00 0xf7 0x04>;
			clocks = <0x0c 0x01 0x2cb>;
			power-domains = <0x09 0x20>;
			resets = <0x0c 0x2cb>;
			status = "disabled";

			ports {
				#address-cells = <0x01>;
				#size-cells = <0x00>;

				port@0 {
					reg = <0x00>;
				};

				port@1 {
					#address-cells = <0x01>;
					#size-cells = <0x00>;
					reg = <0x01>;

					endpoint@0 {
						reg = <0x00>;
						remote-endpoint = <0xbf>;
						phandle = <0x66>;
					};

					endpoint@1 {
						reg = <0x01>;
						remote-endpoint = <0xc0>;
						phandle = <0x69>;
					};

					endpoint@2 {
						reg = <0x02>;
						remote-endpoint = <0xc1>;
						phandle = <0x6c>;
					};

					endpoint@3 {
						reg = <0x03>;
						remote-endpoint = <0xc2>;
						phandle = <0x6e>;
					};
				};
			};
		};

		hdmi@fead0000 {
			compatible = "renesas,r8a7795-hdmi\0renesas,rcar-gen3-hdmi";
			reg = <0x00 0xfead0000 0x00 0x10000>;
			interrupts = <0x00 0x185 0x04>;
			clocks = <0x0c 0x01 0x2d9 0x0c 0x00 0x28>;
			clock-names = "iahb\0isfr";
			power-domains = <0x09 0x20>;
			resets = <0x0c 0x2d9>;
			status = "okay";

			ports {
				#address-cells = <0x01>;
				#size-cells = <0x00>;

				port@0 {
					reg = <0x00>;

					endpoint {
						remote-endpoint = <0xc3>;
						phandle = <0xd2>;
					};
				};

				port@1 {
					reg = <0x01>;

					endpoint {
						remote-endpoint = <0xc4>;
						phandle = <0xda>;
					};
				};

				port@2 {
					reg = <0x02>;

					endpoint {
						remote-endpoint = <0x86>;
						phandle = <0x85>;
					};
				};
			};
		};

		hdmi@feae0000 {
			compatible = "renesas,r8a7795-hdmi\0renesas,rcar-gen3-hdmi";
			reg = <0x00 0xfeae0000 0x00 0x10000>;
			interrupts = <0x00 0x1b4 0x04>;
			clocks = <0x0c 0x01 0x2d8 0x0c 0x00 0x28>;
			clock-names = "iahb\0isfr";
			power-domains = <0x09 0x20>;
			resets = <0x0c 0x2d8>;
			status = "disabled";

			ports {
				#address-cells = <0x01>;
				#size-cells = <0x00>;

				port@0 {
					reg = <0x00>;

					endpoint {
						remote-endpoint = <0xc5>;
						phandle = <0xd3>;
					};
				};

				port@1 {
					reg = <0x01>;
				};

				port@2 {
					reg = <0x02>;
				};
			};
		};

		display@feb00000 {
			compatible = "renesas,du-r8a7795";
			reg = <0x00 0xfeb00000 0x00 0x80000>;
			interrupts = <0x00 0x100 0x04 0x00 0x10c 0x04 0x00 0x10d 0x04 0x00 0x10e 0x04>;
			clocks = <0x0c 0x01 0x2d4 0x0c 0x01 0x2d3 0x0c 0x01 0x2d2 0x0c 0x01 0x2d1 0xc6 0x01 0xc7 0xc8 0xc6 0x02>;
			clock-names = "du.0\0du.1\0du.2\0du.3\0dclkin.0\0dclkin.1\0dclkin.2\0dclkin.3";
			resets = <0x0c 0x2d4 0x0c 0x2d2>;
			reset-names = "du.0\0du.2";
			renesas,cmms = <0xc9 0xca 0xcb 0xcc>;
			renesas,vsps = <0xcd 0x00 0xce 0x00 0xcf 0x00 0xcd 0x01>;
			status = "okay";
			pinctrl-0 = <0xd0>;
			pinctrl-names = "default";

			ports {
				#address-cells = <0x01>;
				#size-cells = <0x00>;

				port@0 {
					reg = <0x00>;

					endpoint {
						remote-endpoint = <0xd1>;
						phandle = <0x29>;
					};
				};

				port@1 {
					reg = <0x01>;

					endpoint {
						remote-endpoint = <0xd2>;
						phandle = <0xc3>;
					};
				};

				port@2 {
					reg = <0x02>;

					endpoint {
						remote-endpoint = <0xd3>;
						phandle = <0xc5>;
					};
				};

				port@3 {
					reg = <0x03>;

					endpoint {
						remote-endpoint = <0xd4>;
						phandle = <0xd5>;
					};
				};
			};
		};

		lvds@feb90000 {
			compatible = "renesas,r8a7795-lvds";
			reg = <0x00 0xfeb90000 0x00 0x14>;
			clocks = <0x0c 0x01 0x2d7>;
			power-domains = <0x09 0x20>;
			resets = <0x0c 0x2d7>;
			status = "okay";

			ports {
				#address-cells = <0x01>;
				#size-cells = <0x00>;

				port@0 {
					reg = <0x00>;

					endpoint {
						remote-endpoint = <0xd5>;
						phandle = <0xd4>;
					};
				};

				port@1 {
					reg = <0x01>;

					endpoint {
						remote-endpoint = <0xd6>;
						phandle = <0xe4>;
					};
				};
			};
		};

		dma-controller@ffc10000 {
			compatible = "renesas,dmac-r8a7795\0renesas,rcar-dmac";
			reg = <0x00 0xffc10000 0x00 0x10000>;
			interrupts = <0x00 0x1c0 0x04 0x00 0x1c1 0x04 0x00 0x1c2 0x04 0x00 0x1c3 0x04 0x00 0x1c4 0x04 0x00 0x1c5 0x04 0x00 0x1c6 0x04 0x00 0x1c7 0x04 0x00 0x1c8 0x04>;
			interrupt-names = "error\0ch0\0ch1\0ch2\0ch3\0ch4\0ch5\0ch6\0ch7";
			clocks = <0x0c 0x01 0x15>;
			clock-names = "fck";
			power-domains = <0x09 0x20>;
			resets = <0x0c 0x15>;
			#dma-cells = <0x01>;
			dma-channels = <0x08>;
		};

		dma-controller@ffc20000 {
			compatible = "renesas,dmac-r8a7795\0renesas,rcar-dmac";
			reg = <0x00 0xffc20000 0x00 0x10000>;
			interrupts = <0x00 0x1d5 0x04 0x00 0x1c9 0x04 0x00 0x1ca 0x04 0x00 0x1cb 0x04 0x00 0x1cc 0x04 0x00 0x1cd 0x04 0x00 0x1ce 0x04 0x00 0x1cf 0x04 0x00 0x1d0 0x04>;
			interrupt-names = "error\0ch0\0ch1\0ch2\0ch3\0ch4\0ch5\0ch6\0ch7";
			clocks = <0x0c 0x01 0x10>;
			clock-names = "fck";
			power-domains = <0x09 0x20>;
			resets = <0x0c 0x10>;
			#dma-cells = <0x01>;
			dma-channels = <0x08>;
		};

		chipid@fff00044 {
			compatible = "renesas,prr";
			reg = <0x00 0xfff00044 0x00 0x04>;
		};

		impdes0 {
			compatible = "renesas,impx4-distributer";
			reg = <0x00 0xffa00000 0x00 0x4000>;
			interrupts = <0x00 0x1b7 0x04>;
			clocks = <0x0c 0x01 0x338>;
			power-domains = <0x09 0x18>;
			interrupt-controller;
			#interrupt-cells = <0x01>;
			phandle = <0xd7>;
		};

		imp0 {
			compatible = "renesas,impx4-legacy";
			reg = <0x00 0xff900000 0x00 0x20000>;
			interrupt-parent = <0xd7>;
			interrupts = <0x00>;
			clocks = <0x0c 0x01 0x338>;
			power-domains = <0x09 0x18>;
		};

		imp1 {
			compatible = "renesas,impx4-legacy";
			reg = <0x00 0xff920000 0x00 0x20000>;
			interrupt-parent = <0xd7>;
			interrupts = <0x01>;
			clocks = <0x0c 0x01 0x338>;
			power-domains = <0x09 0x18>;
		};

		imp2 {
			compatible = "renesas,impx4-legacy";
			reg = <0x00 0xff940000 0x00 0x20000>;
			interrupt-parent = <0xd7>;
			interrupts = <0x02>;
			clocks = <0x0c 0x01 0x338>;
			power-domains = <0x09 0x18>;
		};

		imp3 {
			compatible = "renesas,impx4-legacy";
			reg = <0x00 0xff960000 0x00 0x20000>;
			interrupt-parent = <0xd7>;
			interrupts = <0x03>;
			clocks = <0x0c 0x01 0x338>;
			power-domains = <0x09 0x18>;
		};

		impsc0 {
			compatible = "renesas,impx4-shader";
			reg = <0x00 0xff980000 0x00 0x10000>;
			interrupt-parent = <0xd7>;
			interrupts = <0x04>;
			clocks = <0x0c 0x01 0x338>;
			power-domains = <0x09 0x18>;
		};

		impsc1 {
			compatible = "renesas,impx4-shader";
			reg = <0x00 0xff990000 0x00 0x10000>;
			interrupt-parent = <0xd7>;
			interrupts = <0x05>;
			clocks = <0x0c 0x01 0x338>;
			power-domains = <0x09 0x18>;
		};

		impsl0 {
			compatible = "renesas,impx4-legacy";
			reg = <0x00 0xff9c0000 0x00 0x10000>;
			interrupt-parent = <0xd7>;
			interrupts = <0x0c>;
			clocks = <0x0c 0x01 0x338>;
			power-domains = <0x09 0x18>;
		};

		impdm0 {
			compatible = "renesas,impx5-dmac";
			reg = <0x00 0xffa10000 0x00 0x4000>;
			interrupt-parent = <0xd7>;
			interrupts = <0x10>;
			clocks = <0x0c 0x01 0x338>;
			power-domains = <0x09 0x18>;
		};

		impc0 {
			compatible = "renesas,impx4-memory";
			reg = <0x00 0xffa40000 0x00 0x20000>;
			clocks = <0x0c 0x01 0x338>;
			power-domains = <0x09 0x18>;
		};

		imprtt {
			compatible = "renesas,impx5-rtt";
			reg = <0x00 0xff8d0000 0x00 0x1000 0x00 0xe6150000 0x00 0x1000>;
			interrupts = <0x00 0x189 0x04>;
			clocks = <0x0c 0x01 0x338>;
			power-domains = <0x09 0x18>;
		};

		imrlx4_imr0 {
			compatible = "generic-uio";
			reg = <0x00 0xfe860000 0x00 0x2000>;
			interrupts = <0x00 0xc0 0x04>;
			clocks = <0x0c 0x01 0x337>;
			power-domains = <0x09 0x0e>;
			resets = <0x0c 0x337>;
			linux,uio-name = "imr_00";
			ipmmu-id = <0x07 0x00>;
		};

		imrlx4_imr1 {
			compatible = "generic-uio";
			reg = <0x00 0xfe870000 0x00 0x2000>;
			interrupts = <0x00 0xc1 0x04>;
			clocks = <0x0c 0x01 0x336>;
			power-domains = <0x09 0x0e>;
			resets = <0x0c 0x336>;
			linux,uio-name = "imr_01";
			ipmmu-id = <0x07 0x00>;
		};

		imrlx4_imr2 {
			compatible = "generic-uio";
			reg = <0x00 0xfe880000 0x00 0x2000>;
			interrupts = <0x00 0xc2 0x04>;
			clocks = <0x0c 0x01 0x335>;
			power-domains = <0x09 0x0e>;
			resets = <0x0c 0x335>;
			linux,uio-name = "imr_02";
			ipmmu-id = <0x06 0x01>;
		};

		imrlx4_imr3 {
			compatible = "generic-uio";
			reg = <0x00 0xfe890000 0x00 0x2000>;
			interrupts = <0x00 0xc3 0x04>;
			clocks = <0x0c 0x01 0x334>;
			power-domains = <0x09 0x0e>;
			resets = <0x0c 0x334>;
			linux,uio-name = "imr_03";
			ipmmu-id = <0x06 0x01>;
		};
	};

	thermal-zones {

		emergency {
			polling-delay = <0x3e8>;
			on-temperature = <0x1adb0>;
			off-temperature = <0x17318>;
			target_cpus = <0x02 0x03 0x04 0x05 0x06 0x07 0x08>;
			status = "disabled";
		};

		sensor-thermal1 {
			polling-delay-passive = <0xfa>;
			polling-delay = <0x00>;
			thermal-sensors = <0xd8 0x00>;
			sustainable-power = <0x18a9>;

			trips {

				sensor1-crit {
					temperature = <0x1d4c0>;
					hysteresis = <0x3e8>;
					type = "critical";
				};
			};
		};

		sensor-thermal2 {
			polling-delay-passive = <0xfa>;
			polling-delay = <0x00>;
			thermal-sensors = <0xd8 0x01>;
			sustainable-power = <0x18a9>;

			trips {

				sensor2-crit {
					temperature = <0x1d4c0>;
					hysteresis = <0x3e8>;
					type = "critical";
				};
			};
		};

		sensor-thermal3 {
			polling-delay-passive = <0xfa>;
			polling-delay = <0x00>;
			thermal-sensors = <0xd8 0x02>;
			sustainable-power = <0x18a9>;

			trips {

				trip-point0 {
					temperature = <0x15f90>;
					hysteresis = <0x3e8>;
					type = "passive";
				};

				trip-point1 {
					temperature = <0x186a0>;
					hysteresis = <0x3e8>;
					type = "passive";
					phandle = <0xd9>;
				};

				sensor3-crit {
					temperature = <0x1d4c0>;
					hysteresis = <0x3e8>;
					type = "critical";
				};
			};

			cooling-maps {

				map0 {
					trip = <0xd9>;
					cooling-device = <0x01 0x00 0x02>;
					contribution = <0x400>;
				};

				map1 {
					trip = <0xd9>;
					cooling-device = <0x05 0x00 0x02>;
					contribution = <0x400>;
				};
			};
		};
	};

	timer {
		compatible = "arm,armv8-timer";
		interrupts-extended = <0x19 0x01 0x0d 0xff08 0x19 0x01 0x0e 0xff08 0x19 0x01 0x0b 0xff08 0x19 0x01 0x0a 0xff08>;
	};

	usb3s0 {
		compatible = "fixed-clock";
		#clock-cells = <0x00>;
		clock-frequency = <0x00>;
		phandle = <0x50>;
	};

	usb_extal {
		compatible = "fixed-clock";
		#clock-cells = <0x00>;
		clock-frequency = <0x00>;
		phandle = <0x51>;
	};

	chosen {
		bootargs = "ignore_loglevel rw root=/dev/nfs ip=on";
		stdout-path = "serial0:115200n8";
	};

	audio-clkout {
		compatible = "fixed-clock";
		#clock-cells = <0x00>;
		clock-frequency = <0xbb8000>;
		phandle = <0x24>;
	};

	avb-mch {
		compatible = "renesas,avb-mch-gen3";
		reg = <0x00 0xec5a0100 0x00 0x100>;
		reg-name = "adg_avb";
		clocks = <0x0c 0x01 0x39a>;
		clock-names = "adg";
		resets = <0x0c 0x39a>;
		reset-names = "adg";
	};

	hdmi0-out {
		compatible = "hdmi-connector";
		type = [61 00];

		port {

			endpoint {
				remote-endpoint = <0xda>;
				phandle = <0xc4>;
			};
		};
	};

	keyboard {
		compatible = "gpio-keys";

		key-1 {
			linux,code = <0x02>;
			label = "SW3";
			wakeup-source;
			debounce-interval = <0x14>;
			gpios = <0x2f 0x0b 0x01>;
		};
	};

	leds {
		compatible = "gpio-leds";

		led5 {
			gpios = <0x2f 0x0c 0x00>;
		};

		led6 {
			gpios = <0x2f 0x0d 0x00>;
		};
	};

	regulator0 {
		compatible = "regulator-fixed";
		regulator-name = "fixed-1.8V";
		regulator-min-microvolt = <0x1b7740>;
		regulator-max-microvolt = <0x1b7740>;
		regulator-boot-on;
		regulator-always-on;
		phandle = <0x9f>;
	};

	regulator1 {
		compatible = "regulator-fixed";
		regulator-name = "fixed-3.3V";
		regulator-min-microvolt = <0x325aa0>;
		regulator-max-microvolt = <0x325aa0>;
		regulator-boot-on;
		regulator-always-on;
		phandle = <0x9e>;
	};

	regulator-vcc-sdhi0 {
		compatible = "regulator-fixed";
		regulator-name = "SDHI0 Vcc";
		regulator-min-microvolt = <0x325aa0>;
		regulator-max-microvolt = <0x325aa0>;
		gpio = <0x27 0x02 0x00>;
		enable-active-high;
		phandle = <0x9a>;
	};

	regulator-vccq-sdhi0 {
		compatible = "regulator-gpio";
		regulator-name = "SDHI0 VccQ";
		regulator-min-microvolt = <0x1b7740>;
		regulator-max-microvolt = <0x325aa0>;
		gpios = <0x27 0x01 0x00>;
		gpios-states = <0x01>;
		states = <0x325aa0 0x01 0x1b7740 0x00>;
		phandle = <0x9b>;
	};

	x12 {
		compatible = "fixed-clock";
		#clock-cells = <0x00>;
		clock-frequency = <0x1770000>;
		phandle = <0x25>;
	};

	x23-clock {
		compatible = "fixed-clock";
		#clock-cells = <0x00>;
		clock-frequency = <0x17d7840>;
		phandle = <0x31>;
	};

	memory@48000000 {
		device_type = "memory";
		reg = <0x00 0x48000000 0x00 0x38000000>;
	};

	memory@500000000 {
		device_type = "memory";
		reg = <0x05 0x00 0x00 0x40000000>;
	};

	memory@600000000 {
		device_type = "memory";
		reg = <0x06 0x00 0x00 0x40000000>;
	};

	memory@700000000 {
		device_type = "memory";
		reg = <0x07 0x00 0x00 0x40000000>;
	};

	reserved-memory {
		#address-cells = <0x02>;
		#size-cells = <0x02>;
		ranges;

		linux,lossy_decompress@54000000 {
			no-map;
			reg = <0x00 0x54000000 0x00 0x3000000>;
			phandle = <0xdc>;
		};

		linux,cma@57000000 {
			compatible = "shared-dma-pool";
			reusable;
			reg = <0x00 0x57000000 0x00 0x19000000>;
			linux,cma-default;
		};

		linux,multimedia@70000000 {
			compatible = "shared-dma-pool";
			reusable;
			reg = <0x00 0x70000000 0x00 0x10000000>;
			phandle = <0xdb>;
		};
	};

	mmngr {
		compatible = "renesas,mmngr";
		memory-region = <0xdb 0xdc>;
	};

	mmngrbuf {
		compatible = "renesas,mmngrbuf";
	};

	vspm_if {
		compatible = "renesas,vspm_if";
	};

	versaclk-3 {
		compatible = "fixed-clock";
		#clock-cells = <0x00>;
		clock-frequency = <0x1f78a40>;
		phandle = <0xc7>;
	};

	versaclk-4 {
		compatible = "fixed-clock";
		#clock-cells = <0x00>;
		clock-frequency = <0x1f78a40>;
		phandle = <0xc8>;
	};

	clksndsel {
		#clock-cells = <0x00>;
		compatible = "gpio-mux-clock";
		clocks = <0x26 0x77>;
		select-gpios = <0x28 0x0d 0x00>;
		phandle = <0x2b>;
	};

	regulator-snd_3p3v {
		compatible = "regulator-fixed";
		regulator-name = "snd-3.3v";
		regulator-min-microvolt = <0x325aa0>;
		regulator-max-microvolt = <0x325aa0>;
		phandle = <0x2c>;
	};

	regulator-snd_vcc5v {
		compatible = "regulator-fixed";
		regulator-name = "snd-vcc5v";
		regulator-min-microvolt = <0x4c4b40>;
		regulator-max-microvolt = <0x4c4b40>;
		phandle = <0x2d>;
	};

	regulator-wlan_en {
		compatible = "regulator-fixed";
		regulator-name = "wlan-en-regulator";
		regulator-min-microvolt = <0x325aa0>;
		regulator-max-microvolt = <0x325aa0>;
		gpio = <0xdd 0x04 0x00>;
		startup-delay-us = <0x11170>;
		enable-active-high;
		phandle = <0xa1>;
	};

	regulator@9 {
		compatible = "regulator-fixed";
		regulator-name = "SD WiFi mux";
		regulator-min-microvolt = <0x325aa0>;
		regulator-max-microvolt = <0x325aa0>;
		gpio = <0xdd 0x05 0x00>;
		enable-active-low;
		regulator-always-on;
	};

	regulator@11 {
		compatible = "regulator-fixed";
		regulator-name = "radio_on";
		regulator-min-microvolt = <0x325aa0>;
		regulator-max-microvolt = <0x325aa0>;
		gpio = <0xdd 0x0d 0x00>;
		enable-active-high;
		regulator-always-on;
	};

	regulator@12 {
		compatible = "regulator-fixed";
		regulator-name = "mPCIe 3v3";
		regulator-min-microvolt = <0x325aa0>;
		regulator-max-microvolt = <0x325aa0>;
		gpio = <0xde 0x0e 0x00>;
		enable-active-high;
		phandle = <0xac>;
	};

	regulator@13 {
		compatible = "regulator-fixed";
		regulator-name = "mPCIe 1v8";
		regulator-min-microvolt = <0x1b7740>;
		regulator-max-microvolt = <0x1b7740>;
		gpio = <0xde 0x0f 0x00>;
		startup-delay-us = <0x30d40>;
		enable-active-high;
		phandle = <0xad>;
	};

	regulator@14 {
		compatible = "regulator-fixed";
		regulator-name = "Video-A PWR0";
		regulator-min-microvolt = <0xb71b00>;
		regulator-max-microvolt = <0xb71b00>;
		gpio = <0x33 0x09 0x00>;
		enable-active-high;
		phandle = <0x34>;
	};

	regulator@15 {
		compatible = "regulator-fixed";
		regulator-name = "Video-A PWR1";
		regulator-min-microvolt = <0xb71b00>;
		regulator-max-microvolt = <0xb71b00>;
		gpio = <0x33 0x08 0x00>;
		enable-active-high;
		phandle = <0x35>;
	};

	regulator@16 {
		compatible = "regulator-fixed";
		regulator-name = "Video-A PWR2";
		regulator-min-microvolt = <0xb71b00>;
		regulator-max-microvolt = <0xb71b00>;
		gpio = <0x33 0x0b 0x00>;
		enable-active-high;
		phandle = <0x36>;
	};

	regulator@17 {
		compatible = "regulator-fixed";
		regulator-name = "Video-A PWR3";
		regulator-min-microvolt = <0xb71b00>;
		regulator-max-microvolt = <0xb71b00>;
		gpio = <0x33 0x0a 0x00>;
		enable-active-high;
		phandle = <0x37>;
	};

	kim {
		compatible = "kim";
		shutdown-gpios = <0xdd 0x03 0x00>;
		dev_name = "/dev/ttySC1";
		flow_cntrl = <0x01>;
		baud_rate = <0x32dcd4>;
	};

	btwilink {
		compatible = "btwilink";
	};

	sound@0 {
		compatible = "audio-graph-card";
		label = "ak4613";
		dais = <0xdf 0xe0>;
	};

	sound@1 {
		compatible = "audio-graph-card";
		label = "pcm3168a";
		dais = <0xe1>;
	};

	sound@2 {
		compatible = "audio-graph-card";
		label = "radio";
		dais = <0xe2>;
	};

	sound@3 {
		compatible = "audio-graph-card";
		label = "wl18xx";
		dais = <0xe3>;
	};

	lvds {
		compatible = "panel-lvds";
		width-mm = <0xd2>;
		height-mm = <0x9e>;
		data-mapping = "jeida-24";

		port {

			endpoint {
				remote-endpoint = <0xe4>;
				phandle = <0xd6>;
			};
		};

		panel-timing {
			clock-frequency = <0x3dfd240>;
			hactive = <0x500>;
			vactive = <0x320>;
			hsync-len = <0x28>;
			hfront-porch = <0x50>;
			hback-porch = <0x28>;
			vfront-porch = <0x0e>;
			vback-porch = <0x0e>;
			vsync-len = <0x04>;
		};
	};

	hdmi-out {
		compatible = "hdmi-connector";
		type = [61 00];

		port {

			endpoint {
				remote-endpoint = <0xe5>;
				phandle = <0x2a>;
			};
		};
	};

	si468x@0 {
		compatible = "si,si468x-pcm";
		status = "okay";

		port {

			endpoint {
				remote-endpoint = <0xe6>;
				system-clock-frequency = <0xbb8000>;
				phandle = <0x8b>;
			};
		};
	};

	wl18xx_pcm@0 {
		compatible = "ti,wl18xx-pcm";
		status = "okay";

		port {

			endpoint {
				remote-endpoint = <0xe7>;
				phandle = <0x8d>;
			};
		};
	};

	camera_clk {
		compatible = "fixed-clock";
		#clock-cells = <0x00>;
		clock-frequency = <0x17d7840>;
		clock-output-names = "xclk";
		phandle = <0x41>;
	};
};
